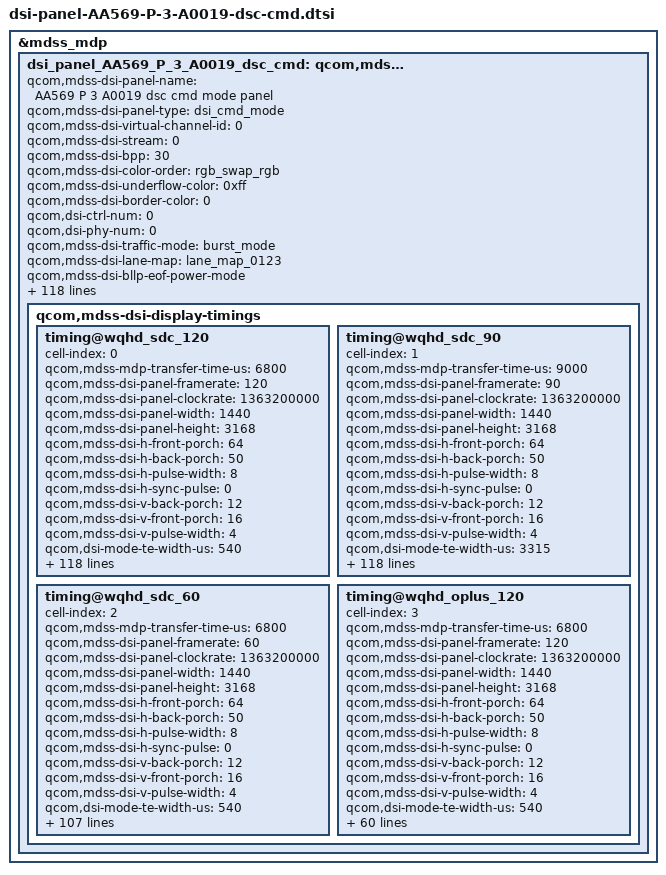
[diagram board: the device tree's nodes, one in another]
&mdss_mdp {
	dsi_panel_AA569_P_3_A0019_dsc_cmd: qcom,mdss_dsi_panel_AA569_P_3_A0019_dsc_cmd {
		qcom,mdss-dsi-panel-name = "AA569 P 3 A0019 dsc cmd mode panel";
		qcom,mdss-dsi-panel-type = "dsi_cmd_mode";
		qcom,mdss-dsi-virtual-channel-id = <0>;
		qcom,mdss-dsi-stream = <0>;
		qcom,mdss-dsi-bpp = <30>;
		qcom,mdss-dsi-color-order = "rgb_swap_rgb";
		qcom,mdss-dsi-underflow-color = <0xff>;
		qcom,mdss-dsi-border-color = <0>;
		qcom,dsi-ctrl-num = <0>;
		qcom,dsi-phy-num = <0>;
		qcom,mdss-dsi-traffic-mode = "burst_mode";
		qcom,mdss-dsi-lane-map = "lane_map_0123";
		qcom,mdss-dsi-bllp-eof-power-mode;
		qcom,mdss-dsi-bllp-power-mode;
		qcom,mdss-dsi-lane-0-state;
		qcom,mdss-dsi-lane-1-state;
		qcom,mdss-dsi-lane-2-state;
		qcom,mdss-dsi-lane-3-state;
		qcom,mdss-dsi-dma-trigger = "trigger_sw";
		qcom,mdss-dsi-mdp-trigger = "none";
		qcom,mdss-dsi-reset-sequence = <1 10>, <0 5>, <1 30>;
		qcom,mdss-pan-physical-width-dimension = <71>;
		qcom,mdss-pan-physical-height-dimension = <158>;
		qcom,mdss-dsi-te-check-enable;
		qcom,mdss-dsi-te-using-te-pin;
		qcom,mdss-dsi-te-pin-select = <1>;
		qcom,mdss-dsi-te-dcs-command = <1>;
		qcom,mdss-dsi-wr-mem-start = <0x2C>;
		qcom,mdss-dsi-wr-mem-continue = <0x3C>;
		//qcom,mdss-dsi-lp11-init;
		qcom,mdss-dsi-init-delay-us = <1000>;
		qcom,mdss-dsi-panel-jitter = <0x4 0x1>;
		/* HDR Setting */
		qcom,mdss-dsi-panel-hdr-enabled;
		qcom,mdss-dsi-panel-hdr-color-primaries = <15635 16450 34000 16000 13250 34500 7500 3000>;
		//update for [MPC15]android.mediapc.cts.PerformanceClassTest#testDisplayHdr pass
		//qcom,mdss-dsi-panel-peak-brightness = <14000000>;
		qcom,mdss-dsi-panel-peak-brightness = <20000000>;
		qcom,mdss-dsi-panel-average-brightness = <2000000>;
		qcom,mdss-dsi-panel-blackness-level = <2000>;

		qcom,mdss-dsi-display-timings {
			timing@wqhd_sdc_120 {
				#include "dsi-panel-AA569-P-3-A0019-common.dtsi"
				#include "dsi-panel-AA569-P-3-A0019-loading-effect.dtsi"
				cell-index = <0>;
				qcom,mdss-mdp-transfer-time-us = <6800>;
				qcom,mdss-dsi-panel-framerate = <120>;
				qcom,mdss-dsi-panel-clockrate = <1363200000>;
				qcom,mdss-dsi-panel-width = <1440>;
				qcom,mdss-dsi-panel-height = <3168>;
				qcom,mdss-dsi-h-front-porch = <64>;
				qcom,mdss-dsi-h-back-porch = <50>;
				qcom,mdss-dsi-h-pulse-width = <8>;
				qcom,mdss-dsi-h-sync-pulse = <0>;
				qcom,mdss-dsi-v-back-porch = <12>;
				qcom,mdss-dsi-v-front-porch = <16>;
				qcom,mdss-dsi-v-pulse-width = <4>;
				qcom,dsi-mode-te-width-us = <540>;

				qcom,mdss-dsi-timing-switch-command = [
					//120Hz
					39 00 00 40 00 00 04 FF 5A A5 00
					15 00 00 40 00 00 02 60 00
					39 00 00 40 00 00 04 FF 5A A5 2D
					39 00 00 40 00 00 03 83 00 00
					15 00 00 40 00 00 02 F2 00
					39 00 00 40 00 00 04 FF 5A A5 02
					39 00 00 40 00 00 04 B0 01 80 00
					39 00 00 00 00 00 04 FF 5A A5 00
				];
				qcom,mdss-dsi-on-command = [
					/* common setting */
					39 00 00 40 00 00 04 FF 5A A5 07
					15 00 00 40 00 00 02 8A 01
					39 00 00 40 00 00 04 FF 5A A5 31
					15 00 00 40 00 00 02 D0 80
					39 00 00 40 00 00 04 FF 5A A5 08
					15 00 00 40 00 00 02 BE 01
					39 00 00 40 00 00 04 FF 5A A5 08
					15 00 00 40 00 00 02 D2 05
					15 00 00 40 00 00 02 D3 0F
					15 00 00 40 00 00 02 D4 40
					15 00 00 40 00 00 02 F5 55
					15 00 00 40 00 00 02 F6 18
					39 00 00 40 00 00 04 FF 5A A5 21
					15 00 00 40 00 00 02 A4 18
					39 00 00 40 00 00 04 FF 5A A5 1F
					39 00 00 40 00 00 19 8F 03 08 50 0E 01 00 00 00 00 00 00 00 00 00 00 00 02 0E 00 00 08 02 00 00
					39 00 00 40 00 00 04 FF 5A A5 05
					15 00 00 40 00 00 02 9E 77
					39 00 00 40 00 00 04 FF 5A A5 14
					15 00 00 40 00 00 02 80 00
					39 00 00 40 00 00 04 FF 5A A5 17
					15 00 00 40 00 00 02 A0 00
					39 00 00 40 00 00 04 FF 5A A5 13
					15 00 00 40 00 00 02 F9 5C
					39 00 00 40 00 00 04 FF 5A A5 05
					15 00 00 40 00 00 02 85 00
					39 00 00 40 00 00 04 FF 5A A5 1C
					39 00 00 40 00 00 13 E2 0A 0A 0A 1A 1A 1A 1A 1A 0A 0A 0A 04 27 12 23 09 46 45
					39 00 00 40 00 00 04 FF 5A A5 01
					15 00 00 40 00 00 02 FB 08
					39 00 00 40 00 00 04 FF 5A A5 09
					39 00 00 40 00 00 07 8E 10 82 00 00 00 00
					39 00 00 40 00 00 04 FF 5A A5 02
					39 00 00 00 00 00 03 88 C0 00
					/* spr in ap */
					39 00 00 40 00 00 04 FF 5A A5 14
					15 00 00 40 00 00 02 82 01		//SPR IN AP MODE
					39 00 00 40 00 00 04 FF 5A A5 07
					15 00 00 40 00 00 02 91 03		//CR CB SETTING
					15 00 00 40 00 00 02 8A 01         //DSC ON
					39 00 00 40 00 00 03 8B A0 21
					39 00 00 00 00 00 64 81 00 00 00 00 00 12 00 00 AB
					                     21 00 0C 60 05 A0 00 16 02 D0
					                     02 D0 01 55 01 E2 00 0A 01 4D
					                     00 3C 00 0D 04 F4 13 A3 08 00
					                     0C 00 07 10 20 00 06 0F 0F 33
					                     0E 1C 2A 38 46 54 62 69 70 77
					                     79 7B 7D 7E 00 82 11 40 19 C0
					                     22 3E 32 7C 3A BA 3A F8 3B 38
					                     3B 38 3B 76 4B 76 4B 74 4B 74
					                     5B B4 73 F4 01 00 00 00 00 00
					/* Skip frame setting */
					39 00 00 40 00 00 04 FF 5A A5 00
					15 00 00 40 00 00 02 5E 01
					15 00 00 40 00 00 02 60 00
					15 00 00 40 00 00 02 61 0D
					39 00 00 40 00 00 04 FF 5A A5 00
					15 00 00 40 00 00 02 6D 01
					39 00 00 40 00 00 04 FF 5A A5 00
					15 00 00 40 00 00 02 35 00
					15 00 00 00 00 00 02 53 20
					//120Hz
					39 00 00 40 00 00 04 FF 5A A5 00
					15 00 00 40 00 00 02 60 00
					39 00 00 40 00 00 04 FF 5A A5 2D
					39 00 00 40 00 00 03 83 00 00
					15 00 00 40 00 00 02 F2 00
					39 00 00 40 00 00 04 FF 5A A5 02
					39 00 00 40 00 00 04 B0 01 80 00
					39 00 00 00 00 00 04 FF 5A A5 00
					// AP SPR
					39 00 00 40 00 00 04 FF 5A A5 02
					39 00 00 40 00 00 03 84 01 05
					// OPR mode
					39 00 00 40 00 00 04 FF 5A A5 1E
					39 00 00 40 00 00 04 98 99 AA 99
					39 00 00 40 00 00 0C 99 88 00 00 88 00 00 88 00 00 08 00
					15 00 00 40 00 00 02 A3 00
					// PeakLumin Dimming Off
					39 00 00 40 00 00 04 FF 5A A5 1E
					15 00 00 40 00 00 02 81 00
					39 00 00 00 00 00 04 FF 5A A5 00
					/* OSC Tracking */
					39 00 00 40 00 00 04 FF 5A A5 22
					39 00 00 40 00 00 08 D8 01 0C 11 10 32 19 19
					39 00 00 40 00 00 0A DC 84 94 BB 00 20 C4 A1 CC 10
					15 00 00 40 00 00 02 DD 01
					15 00 00 40 00 00 02 DE F1
					15 00 00 40 00 00 02 DF 80
					39 00 00 40 00 00 07 E0 02 00 5F 21 00 28
					39 00 00 00 00 00 04 FF 5A A5 00
					/* decreasing step setting */
					39 00 00 40 00 00 04 FF 5A A5 2D
					39 00 00 40 00 00 03 ED 05 00
					15 00 00 40 00 00 02 97 02
					15 00 00 40 00 00 02 98 03
					15 00 00 40 00 00 02 99 0B
					15 00 00 40 00 00 02 9A 17
					39 00 00 40 00 00 03 A0 00 02
					39 00 00 40 00 00 03 A1 02 00
					15 00 00 40 00 00 02 A4 02
					15 00 00 40 00 00 02 A5 02
					15 00 00 40 00 00 02 A6 08
					15 00 00 40 00 00 02 A7 11
					39 00 00 40 00 00 03 AD 00 02
					39 00 00 40 00 00 03 AE 02 00
					39 00 00 00 00 00 04 FF 5A A5 00
					/* partial update esd */
					39 00 00 40 00 00 04 FF 5A A5 08
					15 00 00 00 00 00 02 98 66

					05 00 00 00 78 00 01 11

					39 00 00 40 00 00 04 FF 5A A5 4F
					15 00 00 40 00 00 02 80 01
					39 00 00 40 00 00 04 FF 5A A5 53
					15 00 00 40 00 00 02 F0 01
					39 00 00 40 00 00 04 FF 5A A5 63
					39 00 00 40 00 00 11 F8 00 00 00 00 00 00 00 00 00 00 00 00 00 00 00 00
					39 00 00 40 00 00 11 F9 00 00 00 00 00 00 00 00 00 00 00 00 00 00 00 00
					39 00 00 40 00 00 11 FA 00 00 00 00 00 00 00 00 00 00 00 00 00 00 00 00
					39 00 00 40 00 00 04 FF 5A A5 53
					15 00 00 40 00 00 02 F0 00
					39 00 00 00 00 00 04 FF 5A A5 00
					/* ODC optimize drag shadow */
					39 00 00 40 00 00 04 FF 5A A5 49
					15 00 00 40 00 00 02 D9 03
					15 00 00 40 00 00 02 DA 1E
					15 00 00 40 00 00 02 DB FC
					15 00 00 40 00 00 02 DF 06
					39 00 00 00 00 00 04 FF 5A A5 00
					/* optimize crosstalk */
					39 00 00 40 00 00 04 FF 5A A5 5A
					39 00 00 40 00 00 04 81 07 1A 04
					39 00 00 40 00 00 04 8A F6 17 12
					39 00 00 40 00 00 04 8F 12 3A 33
					39 00 00 40 00 00 04 A5 09 1A 08
					39 00 00 40 00 00 04 B3 30 38 31
					39 00 00 40 00 00 04 C9 08 0D 06
					39 00 00 40 00 00 04 CA 03 06 03
					39 00 00 40 00 00 04 D7 2F 34 2D
					39 00 00 40 00 00 04 FF 5A A5 5B
					39 00 00 40 00 00 04 81 05 09 03
					39 00 00 40 00 00 04 83 02 0C 05
					39 00 00 40 00 00 04 93 00 01 07
					39 00 00 40 00 00 04 94 05 06 05
					39 00 00 40 00 00 04 A5 09 0C 04
					39 00 00 40 00 00 04 A7 FD 0F 04
					39 00 00 40 00 00 04 B7 02 07 07
					39 00 00 40 00 00 04 B8 05 07 06
					39 00 00 40 00 00 04 C9 05 07 02
					39 00 00 40 00 00 04 CA 00 00 00
					39 00 00 40 00 00 04 CB 02 09 FF
					39 00 00 40 00 00 04 DB 00 04 06
					39 00 00 40 00 00 04 DC 00 06 04
					39 00 00 40 00 00 04 FF 5A A5 5C
					39 00 00 40 00 00 04 81 00 03 02
					39 00 00 40 00 00 04 83 01 08 05
					39 00 00 40 00 00 04 93 FF 01 02
					39 00 00 40 00 00 04 94 FF 06 04
					39 00 00 40 00 00 04 A5 01 03 02
					39 00 00 40 00 00 04 B7 FF 01 06
					39 00 00 40 00 00 04 B8 FF 06 03
					39 00 00 00 00 00 04 FF 5A A5 00

					05 00 00 00 00 00 01 29
				];
				/* pwm */
				qcom,mdss-dsi-timming-pwm-switch-onepulse-command = [
					//1pulse code 120hz
					39 00 00 40 00 00 04 FF 5A A5 00
					15 00 00 40 00 00 02 60 0B
					39 00 00 40 00 00 04 FF 5A A5 2D
					39 00 00 40 00 00 03 8E 00 00
					15 00 00 40 00 00 02 F2 00
					39 00 00 40 00 00 04 FF 5A A5 02
					39 00 00 40 00 00 04 B0 01 80 00
					39 00 00 00 00 00 04 FF 5A A5 00
				];
				qcom,mdss-dsi-pwm-switch-mode0-command= [
					39 00 00 40 00 00 04 FF 5A A5 4F
					15 00 00 40 00 00 02 88 78
					39 00 00 40 00 00 04 FF 5A A5 01
					39 00 00 40 00 00 07 80 0C 00 00 00 10 19
					39 00 00 40 00 00 04 FF 5A A5 0B
					39 00 00 40 00 00 04 89 00 2F 17
					39 00 00 40 00 00 04 8A 00 00 05
					39 00 00 40 00 00 04 A8 00 0F 37
					39 00 00 40 00 00 04 A9 00 00 1F
					39 00 00 40 00 00 04 FF 5A A5 23
					15 00 00 40 00 00 02 AC 5A
					39 00 00 40 00 00 04 FF 5A A5 51
					39 00 00 40 00 00 07 C0 D6 D6 54 BE 11 01
					39 00 00 40 00 00 07 C1 78 64 64 5A 00 00
					39 00 00 40 00 00 07 C2 50 50 50 04 00 10
					39 00 00 40 00 00 04 FF 5A A5 51
					39 00 00 40 00 00 07 A0 5F 5F 5F 55 22 22
					39 00 00 40 00 00 07 A1 5A 5A 4E 75 22 22
					39 00 00 40 00 00 07 A2 70 6C 69 48 22 22
					39 00 00 40 00 00 04 FF 5A A5 52
					39 00 00 40 00 00 07 80 DA DA 57 C4 11 01
					39 00 00 40 00 00 07 81 7E 6A 70 5F 00 00
					39 00 00 40 00 00 07 82 55 56 54 04 00 10
					39 00 00 40 00 00 04 FF 5A A5 53
					39 00 00 40 00 00 03 85 CC E1
					39 00 00 40 00 00 04 FF 5A A5 1E
					39 00 00 40 00 00 1F 8E AA 62 EA EA EA AA EA EA EA EA AA EA EA EA EA AA EA EA EA EA AA EA F2 F2 F2 AA F2 F2 F2 F2
					39 00 00 40 00 00 1F 93 AA 62 EA EA EA AA EA EA EA EA AA EA EA EA EA AA EA EA EA EA AA EA F2 F2 F2 AA F2 F2 F2 F2
					39 00 00 40 00 00 04 FF 5A A5 24
					39 00 00 40 00 00 09 AC 10 ED 0F FE 0D BB 0A 81
					39 00 00 40 00 00 09 AD 06 E9 04 4D 04 3B 03 A2
					39 00 00 40 00 00 09 AE 02 8E 01 A0 00 01 00 00
					39 00 00 40 00 00 04 FF 5A A5 00
					15 00 00 40 00 00 02 60 00
					39 00 00 40 00 00 04 FF 5A A5 4F
					15 00 00 40 00 00 02 8A 78
					39 00 00 40 00 00 04 FF 5A A5 1E
					39 00 00 40 00 00 1F 8E AA 62 EA EA EA AA EA EA EA EA AA EA EA EA EA AA EA EA EA EA AA EA EA EA EA AA EA EA EA EA
					39 00 00 40 00 00 1F 93 AA 62 EA EA EA AA EA EA EA EA AA EA EA EA EA AA EA EA EA EA AA EA EA EA EA AA EA EA EA EA
					39 00 00 40 00 00 04 FF 5A A5 4F
					15 00 00 40 00 00 02 8A 78
					39 00 00 40 00 00 04 FF 5A A5 4F
					15 00 00 00 00 00 02 8B 78
				];
				qcom,mdss-dsi-pwm-switch-mode2-command = [
					39 00 00 40 00 00 04 FF 5A A5 4F
					15 00 00 40 00 00 02 88 78
					39 00 00 40 00 00 04 FF 5A A5 51
					39 00 00 40 00 00 07 C0 D6 D6 54 BE 11 01
					39 00 00 40 00 00 07 C1 78 64 64 5A 00 00
					39 00 00 40 00 00 07 C2 32 32 32 04 00 10
					39 00 00 40 00 00 04 FF 5A A5 51
					39 00 00 40 00 00 07 A0 44 44 45 3A 22 22
					39 00 00 40 00 00 07 A1 41 44 41 63 22 22
					39 00 00 40 00 00 07 A2 60 5D 5D 48 22 22
					39 00 00 40 00 00 04 FF 5A A5 52
					39 00 00 40 00 00 07 80 D6 D6 53 BC 11 01
					39 00 00 40 00 00 07 81 74 63 63 55 00 00
					39 00 00 40 00 00 07 82 2F 2F 2F 04 00 10
					39 00 00 40 00 00 04 FF 5A A5 53
					39 00 00 40 00 00 03 85 CC E3
					39 00 00 40 00 00 04 FF 5A A5 1E
					39 00 00 40 00 00 1F 8E AA 54 DC DC DC AA DC DC DC DC AA DC DC DC DC AA DC DC DC DC AA DC D0 D0 D0 AA D0 D0 D0 D0
					39 00 00 40 00 00 1F 93 AA 54 DC DC DC AA DC DC DC DC AA DC DC DC DC AA DC DC DC DC AA DC D0 D0 D0 AA D0 D0 D0 D0
					39 00 00 40 00 00 04 FF 5A A5 24
					39 00 00 40 00 00 09 AC 10 ED 0F FE 0D BB 0A 81
					39 00 00 40 00 00 09 AD 06 E9 04 4D 03 A2 02 8E
					39 00 00 40 00 00 09 AE 01 A0 00 01 00 00 00 00
					39 00 00 40 00 00 04 FF 5A A5 00
					15 00 00 40 00 00 02 60 0B
					39 00 00 40 00 00 04 FF 5A A5 4F
					15 00 00 40 00 00 02 8A 78
					39 00 00 40 00 00 04 FF 5A A5 01
					39 00 00 40 00 00 07 80 0C 00 00 00 10 29
					39 00 00 40 00 00 04 FF 5A A5 23
					15 00 00 40 00 00 02 AC 1A
					39 00 00 40 00 00 04 FF 5A A5 0B
					39 00 00 40 00 00 04 89 00 3F 07
					39 00 00 40 00 00 04 8A 00 05 05
					39 00 00 40 00 00 04 A8 00 0F 37
					39 00 00 40 00 00 04 A9 00 0B 1F
					39 00 00 40 00 00 04 FF 5A A5 1E
					39 00 00 40 00 00 1F 8E AA 62 EA EA EA AA EA EA EA EA AA EA EA EA EA AA EA EA EA EA AA EA EA EA EA AA EA EA EA EA
					39 00 00 40 00 00 1F 93 AA 62 EA EA EA AA EA EA EA EA AA EA EA EA EA AA EA EA EA EA AA EA EA EA EA AA EA EA EA EA
					39 00 00 40 00 00 04 FF 5A A5 4F
					15 00 00 40 00 00 02 8A 78
					39 00 00 40 00 00 04 FF 5A A5 4F
					15 00 00 00 00 00 02 8B 78
				];
				qcom,mdss-dsi-pwm-switch-mode2-panel-on-command = [
					39 00 00 40 00 00 04 FF 5A A5 4F
					15 00 00 40 00 00 02 88 78
					39 00 00 40 00 00 04 FF 5A A5 51
					39 00 00 40 00 00 07 C0 D6 D6 54 BE 11 01
					39 00 00 40 00 00 07 C1 78 64 64 5A 00 00
					39 00 00 40 00 00 07 C2 32 32 32 04 00 10
					39 00 00 40 00 00 04 FF 5A A5 51
					39 00 00 40 00 00 07 A0 44 44 45 3A 22 22
					39 00 00 40 00 00 07 A1 41 44 41 63 22 22
					39 00 00 40 00 00 07 A2 60 5D 5D 48 22 22
					39 00 00 40 00 00 04 FF 5A A5 52
					39 00 00 40 00 00 07 80 D6 D6 53 BC 11 01
					39 00 00 40 00 00 07 81 74 63 63 55 00 00
					39 00 00 40 00 00 07 82 2F 2F 2F 04 00 10
					39 00 00 40 00 00 04 FF 5A A5 53
					39 00 00 40 00 00 03 85 CC E3
					39 00 00 40 00 00 04 FF 5A A5 1E
					39 00 00 40 00 00 1F 8E AA 54 DC DC DC AA DC DC DC DC AA DC DC DC DC AA DC DC DC DC AA DC D0 D0 D0 AA D0 D0 D0 D0
					39 00 00 40 00 00 1F 93 AA 54 DC DC DC AA DC DC DC DC AA DC DC DC DC AA DC DC DC DC AA DC D0 D0 D0 AA D0 D0 D0 D0
					39 00 00 40 00 00 04 FF 5A A5 24
					39 00 00 40 00 00 09 AC 10 ED 0F FE 0D BB 0A 81
					39 00 00 40 00 00 09 AD 06 E9 04 4D 03 A2 02 8E
					39 00 00 40 00 00 09 AE 01 A0 00 01 00 00 00 00
					39 00 00 40 00 00 04 FF 5A A5 00
					15 00 00 40 00 00 02 60 0B
					39 00 00 40 00 00 04 FF 5A A5 4F
					15 00 00 40 00 00 02 8A 78
					39 00 00 40 00 00 04 FF 5A A5 01
					39 00 00 40 00 00 07 80 0C 00 00 00 10 29
					39 00 00 40 00 00 04 FF 5A A5 23
					15 00 00 40 00 00 02 AC 1A
					39 00 00 40 00 00 04 FF 5A A5 0B
					39 00 00 40 00 00 04 89 00 3F 07
					39 00 00 40 00 00 04 8A 00 05 05
					39 00 00 40 00 00 04 A8 00 0F 37
					39 00 00 40 00 00 04 A9 00 0B 1F
					39 00 00 40 00 00 04 FF 5A A5 1E
					39 00 00 40 00 00 1F 8E AA 62 EA EA EA AA EA EA EA EA AA EA EA EA EA AA EA EA EA EA AA EA EA EA EA AA EA EA EA EA
					39 00 00 40 00 00 1F 93 AA 62 EA EA EA AA EA EA EA EA AA EA EA EA EA AA EA EA EA EA AA EA EA EA EA AA EA EA EA EA
					39 00 00 40 00 00 04 FF 5A A5 4F
					15 00 00 40 00 00 02 8A 78
					39 00 00 40 00 00 04 FF 5A A5 4F
					15 00 00 00 09 00 02 8B 78
				];
				qcom,mdss-dsi-pwm-switch-low-bl-command = [
					39 00 00 40 00 00 04 FF 5A A5 4F
					15 00 00 40 00 00 02 88 78
					39 00 00 40 00 00 04 FF 5A A5 01
					39 00 00 40 00 00 07 80 0C 00 00 00 10 19
					39 00 00 40 00 00 04 FF 5A A5 0B
					39 00 00 40 00 00 04 89 00 2F 17
					39 00 00 40 00 00 04 8A 00 00 05
					39 00 00 40 00 00 04 A8 00 0F 37
					39 00 00 40 00 00 04 A9 00 00 1F
					39 00 00 40 00 00 04 FF 5A A5 23
					15 00 00 40 00 00 02 AC 5A
					39 00 00 40 00 00 04 FF 5A A5 51
					39 00 00 40 00 00 07 C0 D6 D6 54 BE 11 01
					39 00 00 40 00 00 07 C1 78 64 64 5A 00 00
					39 00 00 40 00 00 07 C2 50 50 50 04 00 10
					39 00 00 40 00 00 04 FF 5A A5 51
					39 00 00 40 00 00 07 A0 5F 5F 5F 55 22 22
					39 00 00 40 00 00 07 A1 5A 5A 4E 75 22 22
					39 00 00 40 00 00 07 A2 70 6C 69 48 22 22
					39 00 00 40 00 00 04 FF 5A A5 52
					39 00 00 40 00 00 07 80 DA DA 57 C4 11 01
					39 00 00 40 00 00 07 81 7E 6A 70 5F 00 00
					39 00 00 40 00 00 07 82 55 56 54 04 00 10
					39 00 00 40 00 00 04 FF 5A A5 53
					39 00 00 40 00 00 03 85 CC E1
					39 00 00 40 00 00 04 FF 5A A5 1E
					39 00 00 40 00 00 1F 8E AA 62 EA EA EA AA EA EA EA EA AA EA EA EA EA AA EA EA EA EA AA EA F2 F2 F2 AA F2 F2 F2 F2
					39 00 00 40 00 00 1F 93 AA 62 EA EA EA AA EA EA EA EA AA EA EA EA EA AA EA EA EA EA AA EA F2 F2 F2 AA F2 F2 F2 F2
					39 00 00 40 00 00 04 FF 5A A5 00
					39 00 00 40 00 00 03 51 04 4D
					15 00 00 40 00 00 02 60 00
					39 00 00 40 00 00 04 FF 5A A5 24
					39 00 00 40 00 00 09 AC 10 ED 0F FE 0D BB 0A 81
					39 00 00 40 00 00 09 AD 06 E9 04 4D 04 3B 03 A2
					39 00 00 40 00 00 09 AE 02 8E 01 A0 00 01 00 00
					39 00 00 40 00 00 04 FF 5A A5 4F
					15 00 00 40 00 00 02 8A 78
					39 00 00 40 00 00 04 FF 5A A5 1E
					39 00 00 40 00 00 1F 8E AA 62 EA EA EA AA EA EA EA EA AA EA EA EA EA AA EA EA EA EA AA EA EA EA EA AA EA EA EA EA
					39 00 00 40 00 00 1F 93 AA 62 EA EA EA AA EA EA EA EA AA EA EA EA EA AA EA EA EA EA AA EA EA EA EA AA EA EA EA EA
					39 00 00 40 00 00 04 FF 5A A5 4F
					15 00 00 00 00 00 02 8B 78
				];
				qcom,mdss-dsi-pwm-switch-high-bl-command = [
					39 00 00 40 00 00 04 FF 5A A5 4F
					15 00 00 40 00 00 02 88 78
					39 00 00 40 00 00 04 FF 5A A5 51
					39 00 00 40 00 00 07 C0 D6 D6 54 BE 11 01
					39 00 00 40 00 00 07 C1 78 64 64 5A 00 00
					39 00 00 40 00 00 07 C2 32 32 32 04 00 10
					39 00 00 40 00 00 04 FF 5A A5 51
					39 00 00 40 00 00 07 A0 44 44 45 3A 22 22
					39 00 00 40 00 00 07 A1 41 44 41 63 22 22
					39 00 00 40 00 00 07 A2 60 5D 5D 48 22 22
					39 00 00 40 00 00 04 FF 5A A5 52
					39 00 00 40 00 00 07 80 D6 D6 53 BC 11 01
					39 00 00 40 00 00 07 81 74 63 63 55 00 00
					39 00 00 40 00 00 07 82 2F 2F 2F 04 00 10
					39 00 00 40 00 00 04 FF 5A A5 53
					39 00 00 40 00 00 03 85 CC E3
					39 00 00 40 00 00 04 FF 5A A5 1E
					39 00 00 40 00 00 1F 8E AA 54 DC DC DC AA DC DC DC DC AA DC DC DC DC AA DC DC DC DC AA DC D0 D0 D0 AA D0 D0 D0 D0
					39 00 00 40 00 00 1F 93 AA 54 DC DC DC AA DC DC DC DC AA DC DC DC DC AA DC DC DC DC AA DC D0 D0 D0 AA D0 D0 D0 D0
					39 00 00 40 00 00 04 FF 5A A5 00
					39 00 00 40 00 00 03 51 04 4D
					15 00 00 40 00 00 02 60 0B
					39 00 00 40 00 00 04 FF 5A A5 24
					39 00 00 40 00 00 09 AC 10 ED 0F FE 0D BB 0A 81
					39 00 00 40 00 00 09 AD 06 E9 04 4D 03 A2 02 8E
					39 00 00 40 00 00 09 AE 01 A0 00 01 00 00 00 00
					39 00 00 40 00 00 04 FF 5A A5 4F
					15 00 00 40 00 00 02 8A 78
					39 00 00 40 00 00 04 FF 5A A5 01
					39 00 00 40 00 00 07 80 0C 00 00 00 10 29
					39 00 00 40 00 00 04 FF 5A A5 23
					15 00 00 40 00 00 02 AC 1A
					39 00 00 40 00 00 04 FF 5A A5 0B
					39 00 00 40 00 00 04 89 00 3F 07
					39 00 00 40 00 00 04 8A 00 05 05
					39 00 00 40 00 00 04 A8 00 0F 37
					39 00 00 40 00 00 04 A9 00 0B 1F
					39 00 00 40 00 00 04 FF 5A A5 1E
					39 00 00 40 00 00 1F 8E AA 62 EA EA EA AA EA EA EA EA AA EA EA EA EA AA EA EA EA EA AA EA EA EA EA AA EA EA EA EA
					39 00 00 40 00 00 1F 93 AA 62 EA EA EA AA EA EA EA EA AA EA EA EA EA AA EA EA EA EA AA EA EA EA EA AA EA EA EA EA
					39 00 00 40 00 00 04 FF 5A A5 4F
					15 00 00 00 00 00 02 8B 78
				];

				//qcom,panel-roi-alignment=<1080 44 1080 44 1080 44>;
				//qcom,partial-update-enabled = "single_roi";

				qcom,lm-split = <720 720>;
				qcom,mdss-dsc-slice-height = <22>;
				qcom,mdss-dsc-slice-width = <720>;
			};
			timing@wqhd_sdc_90 {
				#include "dsi-panel-AA569-P-3-A0019-common.dtsi"
				#include "dsi-panel-AA569-P-3-A0019-loading-effect.dtsi"
				cell-index = <1>;
				qcom,mdss-mdp-transfer-time-us = <9000>;
				qcom,mdss-dsi-panel-framerate = <90>;
				qcom,mdss-dsi-panel-clockrate = <1363200000>;
				qcom,mdss-dsi-panel-width = <1440>;
				qcom,mdss-dsi-panel-height = <3168>;
				qcom,mdss-dsi-h-front-porch = <64>;
				qcom,mdss-dsi-h-back-porch = <50>;
				qcom,mdss-dsi-h-pulse-width = <8>;
				qcom,mdss-dsi-h-sync-pulse = <0>;
				qcom,mdss-dsi-v-back-porch = <12>;
				qcom,mdss-dsi-v-front-porch = <16>;
				qcom,mdss-dsi-v-pulse-width = <4>;
				qcom,dsi-mode-te-width-us = <3315>;

				qcom,mdss-dsi-timing-switch-command = [
					//90Hz
					39 00 00 40 00 00 04 FF 5A A5 00
					15 00 00 40 00 00 02 60 07
					39 00 00 40 00 00 04 FF 5A A5 2D
					39 00 00 40 00 00 03 8A 00 00
					15 00 00 40 00 00 02 F2 00
					39 00 00 40 00 00 04 FF 5A A5 02
					39 00 00 40 00 00 04 B0 01 80 00
					39 00 00 00 00 00 04 FF 5A A5 00
				];
				qcom,mdss-dsi-on-command = [
					/* common setting */
					39 00 00 40 00 00 04 FF 5A A5 07
					15 00 00 40 00 00 02 8A 01
					39 00 00 40 00 00 04 FF 5A A5 31
					15 00 00 40 00 00 02 D0 80
					39 00 00 40 00 00 04 FF 5A A5 08
					15 00 00 40 00 00 02 BE 01
					39 00 00 40 00 00 04 FF 5A A5 08
					15 00 00 40 00 00 02 D2 05
					15 00 00 40 00 00 02 D3 0F
					15 00 00 40 00 00 02 D4 40
					15 00 00 40 00 00 02 F5 55
					15 00 00 40 00 00 02 F6 18
					39 00 00 40 00 00 04 FF 5A A5 21
					15 00 00 40 00 00 02 A4 18
					39 00 00 40 00 00 04 FF 5A A5 1F
					39 00 00 40 00 00 19 8F 03 08 50 0E 01 00 00 00 00 00 00 00 00 00 00 00 02 0E 00 00 08 02 00 00
					39 00 00 40 00 00 04 FF 5A A5 05
					15 00 00 40 00 00 02 9E 77
					39 00 00 40 00 00 04 FF 5A A5 14
					15 00 00 40 00 00 02 80 00
					39 00 00 40 00 00 04 FF 5A A5 17
					15 00 00 40 00 00 02 A0 00
					39 00 00 40 00 00 04 FF 5A A5 13
					15 00 00 40 00 00 02 F9 5C
					39 00 00 40 00 00 04 FF 5A A5 05
					15 00 00 40 00 00 02 85 00
					39 00 00 40 00 00 04 FF 5A A5 1C
					39 00 00 40 00 00 13 E2 0A 0A 0A 1A 1A 1A 1A 1A 0A 0A 0A 04 27 12 23 09 46 45
					39 00 00 40 00 00 04 FF 5A A5 01
					15 00 00 40 00 00 02 FB 08
					39 00 00 40 00 00 04 FF 5A A5 09
					39 00 00 40 00 00 07 8E 10 82 00 00 00 00
					39 00 00 40 00 00 04 FF 5A A5 02
					39 00 00 00 00 00 03 88 C0 00
					/* spr in ap */
					39 00 00 40 00 00 04 FF 5A A5 14
					15 00 00 40 00 00 02 82 01		//SPR IN AP MODE
					39 00 00 40 00 00 04 FF 5A A5 07
					15 00 00 40 00 00 02 91 03		//CR CB SETTING
					15 00 00 40 00 00 02 8A 01         //DSC ON
					39 00 00 40 00 00 03 8B A0 21
					39 00 00 00 00 00 64 81 00 00 00 00 00 12 00 00 AB
					                     21 00 0C 60 05 A0 00 16 02 D0
					                     02 D0 01 55 01 E2 00 0A 01 4D
					                     00 3C 00 0D 04 F4 13 A3 08 00
					                     0C 00 07 10 20 00 06 0F 0F 33
					                     0E 1C 2A 38 46 54 62 69 70 77
					                     79 7B 7D 7E 00 82 11 40 19 C0
					                     22 3E 32 7C 3A BA 3A F8 3B 38
					                     3B 38 3B 76 4B 76 4B 74 4B 74
					                     5B B4 73 F4 01 00 00 00 00 00
					/* Skip frame setting */
					39 00 00 40 00 00 04 FF 5A A5 00
					15 00 00 40 00 00 02 5E 01
					15 00 00 40 00 00 02 60 00
					15 00 00 40 00 00 02 61 0D
					39 00 00 40 00 00 04 FF 5A A5 00
					15 00 00 40 00 00 02 6D 01
					39 00 00 40 00 00 04 FF 5A A5 00
					15 00 00 40 00 00 02 35 00
					15 00 00 00 00 00 02 53 20
					//90Hz
					39 00 00 40 00 00 04 FF 5A A5 00
					15 00 00 40 00 00 02 60 07
					39 00 00 40 00 00 04 FF 5A A5 2D
					39 00 00 40 00 00 03 8A 00 00
					15 00 00 40 00 00 02 F2 00
					39 00 00 40 00 00 04 FF 5A A5 02
					39 00 00 40 00 00 04 B0 01 80 00
					39 00 00 00 00 00 04 FF 5A A5 00
					// AP SPR
					39 00 00 40 00 00 04 FF 5A A5 02
					39 00 00 40 00 00 03 84 01 05
					// OPR mode
					39 00 00 40 00 00 04 FF 5A A5 1E
					39 00 00 40 00 00 04 98 99 AA 99
					39 00 00 40 00 00 0C 99 88 00 00 88 00 00 88 00 00 08 00
					15 00 00 40 00 00 02 A3 00
					// PeakLumin Dimming Off
					39 00 00 40 00 00 04 FF 5A A5 1E
					15 00 00 40 00 00 02 81 00
					39 00 00 00 00 00 04 FF 5A A5 00
					/* OSC Tracking */
					39 00 00 40 00 00 04 FF 5A A5 22
					39 00 00 40 00 00 08 D8 01 0C 11 10 32 19 19
					39 00 00 40 00 00 0A DC 84 94 BB 00 20 C4 A1 CC 10
					15 00 00 40 00 00 02 DD 01
					15 00 00 40 00 00 02 DE F1
					15 00 00 40 00 00 02 DF 80
					39 00 00 40 00 00 07 E0 02 00 5F 21 00 28
					39 00 00 00 00 00 04 FF 5A A5 00
					/* decreasing step setting */
					39 00 00 40 00 00 04 FF 5A A5 2D
					39 00 00 40 00 00 03 ED 05 00
					15 00 00 40 00 00 02 97 02
					15 00 00 40 00 00 02 98 03
					15 00 00 40 00 00 02 99 0B
					15 00 00 40 00 00 02 9A 17
					39 00 00 40 00 00 03 A0 00 02
					39 00 00 40 00 00 03 A1 02 00
					15 00 00 40 00 00 02 A4 02
					15 00 00 40 00 00 02 A5 02
					15 00 00 40 00 00 02 A6 08
					15 00 00 40 00 00 02 A7 11
					39 00 00 40 00 00 03 AD 00 02
					39 00 00 40 00 00 03 AE 02 00
					39 00 00 00 00 00 04 FF 5A A5 00
					/* partial update esd */
					39 00 00 40 00 00 04 FF 5A A5 08
					15 00 00 00 00 00 02 98 66

					05 00 00 00 78 00 01 11

					39 00 00 40 00 00 04 FF 5A A5 4F
					15 00 00 40 00 00 02 80 01
					39 00 00 40 00 00 04 FF 5A A5 53
					15 00 00 40 00 00 02 F0 01
					39 00 00 40 00 00 04 FF 5A A5 63
					39 00 00 40 00 00 11 F8 00 00 00 00 00 00 00 00 00 00 00 00 00 00 00 00
					39 00 00 40 00 00 11 F9 00 00 00 00 00 00 00 00 00 00 00 00 00 00 00 00
					39 00 00 40 00 00 11 FA 00 00 00 00 00 00 00 00 00 00 00 00 00 00 00 00
					39 00 00 40 00 00 04 FF 5A A5 53
					15 00 00 40 00 00 02 F0 00
					39 00 00 00 00 00 04 FF 5A A5 00
					/* ODC optimize drag shadow */
					39 00 00 40 00 00 04 FF 5A A5 49
					15 00 00 40 00 00 02 D9 03
					15 00 00 40 00 00 02 DA 1E
					15 00 00 40 00 00 02 DB FC
					15 00 00 40 00 00 02 DF 06
					39 00 00 00 00 00 04 FF 5A A5 00
					/* optimize crosstalk */
					39 00 00 40 00 00 04 FF 5A A5 5A
					39 00 00 40 00 00 04 81 07 1A 04
					39 00 00 40 00 00 04 8A F6 17 12
					39 00 00 40 00 00 04 8F 12 3A 33
					39 00 00 40 00 00 04 A5 09 1A 08
					39 00 00 40 00 00 04 B3 30 38 31
					39 00 00 40 00 00 04 C9 08 0D 06
					39 00 00 40 00 00 04 CA 03 06 03
					39 00 00 40 00 00 04 D7 2F 34 2D
					39 00 00 40 00 00 04 FF 5A A5 5B
					39 00 00 40 00 00 04 81 05 09 03
					39 00 00 40 00 00 04 83 02 0C 05
					39 00 00 40 00 00 04 93 00 01 07
					39 00 00 40 00 00 04 94 05 06 05
					39 00 00 40 00 00 04 A5 09 0C 04
					39 00 00 40 00 00 04 A7 FD 0F 04
					39 00 00 40 00 00 04 B7 02 07 07
					39 00 00 40 00 00 04 B8 05 07 06
					39 00 00 40 00 00 04 C9 05 07 02
					39 00 00 40 00 00 04 CA 00 00 00
					39 00 00 40 00 00 04 CB 02 09 FF
					39 00 00 40 00 00 04 DB 00 04 06
					39 00 00 40 00 00 04 DC 00 06 04
					39 00 00 40 00 00 04 FF 5A A5 5C
					39 00 00 40 00 00 04 81 00 03 02
					39 00 00 40 00 00 04 83 01 08 05
					39 00 00 40 00 00 04 93 FF 01 02
					39 00 00 40 00 00 04 94 FF 06 04
					39 00 00 40 00 00 04 A5 01 03 02
					39 00 00 40 00 00 04 B7 FF 01 06
					39 00 00 40 00 00 04 B8 FF 06 03
					39 00 00 00 00 00 04 FF 5A A5 00

					05 00 00 00 00 00 01 29
				];
				/* pwm */
				qcom,mdss-dsi-timming-pwm-switch-onepulse-command = [
					//1pulse code 90hz
					39 00 00 40 00 00 04 FF 5A A5 00
					15 00 00 40 00 00 02 60 0C
					39 00 00 40 00 00 04 FF 5A A5 2D
					39 00 00 40 00 00 03 8F 00 00
					15 00 00 40 00 00 02 F2 00
					39 00 00 40 00 00 04 FF 5A A5 02
					39 00 00 40 00 00 04 B0 01 80 00
					39 00 00 00 00 00 04 FF 5A A5 00
				];
				qcom,mdss-dsi-pwm-switch-mode0-command= [
					39 00 00 40 00 00 04 FF 5A A5 4F
					15 00 00 40 00 00 02 88 78
					39 00 00 40 00 00 04 FF 5A A5 01
					39 00 00 40 00 00 07 80 0C 00 00 00 10 19
					39 00 00 40 00 00 04 FF 5A A5 0B
					39 00 00 40 00 00 04 89 00 2F 17
					39 00 00 40 00 00 04 8A 00 00 05
					39 00 00 40 00 00 04 A8 00 0F 37
					39 00 00 40 00 00 04 A9 00 00 1F
					39 00 00 40 00 00 04 FF 5A A5 23
					15 00 00 40 00 00 02 AC 5A
					39 00 00 40 00 00 04 FF 5A A5 51
					39 00 00 40 00 00 07 C0 D6 D6 54 BE 11 01
					39 00 00 40 00 00 07 C1 78 64 64 5A 00 00
					39 00 00 40 00 00 07 C2 50 50 50 04 00 10
					39 00 00 40 00 00 04 FF 5A A5 51
					39 00 00 40 00 00 07 A0 5F 5F 5F 55 22 22
					39 00 00 40 00 00 07 A1 5A 5A 4E 75 22 22
					39 00 00 40 00 00 07 A2 70 6C 69 48 22 22
					39 00 00 40 00 00 04 FF 5A A5 52
					39 00 00 40 00 00 07 80 DA DA 57 C4 11 01
					39 00 00 40 00 00 07 81 7E 6A 70 5F 00 00
					39 00 00 40 00 00 07 82 55 56 54 04 00 10
					39 00 00 40 00 00 04 FF 5A A5 53
					39 00 00 40 00 00 03 85 CC E1
					39 00 00 40 00 00 04 FF 5A A5 1E
					39 00 00 40 00 00 1F 8E AA 62 EA EA EA AA EA EA EA EA AA EA EA EA EA AA EA EA EA EA AA EA F2 F2 F2 AA F2 F2 F2 F2
					39 00 00 40 00 00 1F 93 AA 62 EA EA EA AA EA EA EA EA AA EA EA EA EA AA EA EA EA EA AA EA F2 F2 F2 AA F2 F2 F2 F2
					39 00 00 40 00 00 04 FF 5A A5 24
					39 00 00 40 00 00 09 AC 10 ED 0F FE 0D BB 0A 81
					39 00 00 40 00 00 09 AD 06 E9 04 4D 04 3B 03 A2
					39 00 00 40 00 00 09 AE 02 8E 01 A0 00 01 00 00
					39 00 00 40 00 00 04 FF 5A A5 00
					15 00 00 40 00 00 02 60 07
					39 00 00 40 00 00 04 FF 5A A5 4F
					15 00 00 40 00 00 02 8A 78
					39 00 00 40 00 00 04 FF 5A A5 1E
					39 00 00 40 00 00 1F 8E AA 62 EA EA EA AA EA EA EA EA AA EA EA EA EA AA EA EA EA EA AA EA EA EA EA AA EA EA EA EA
					39 00 00 40 00 00 1F 93 AA 62 EA EA EA AA EA EA EA EA AA EA EA EA EA AA EA EA EA EA AA EA EA EA EA AA EA EA EA EA
					39 00 00 40 00 00 04 FF 5A A5 4F
					15 00 00 40 00 00 02 8A 78
					39 00 00 40 00 00 04 FF 5A A5 4F
					15 00 00 00 00 00 02 8B 78
				];
				qcom,mdss-dsi-pwm-switch-mode2-command = [
					39 00 00 40 00 00 04 FF 5A A5 4F
					15 00 00 40 00 00 02 88 78
					39 00 00 40 00 00 04 FF 5A A5 51
					39 00 00 40 00 00 07 C0 D6 D6 54 BE 11 01
					39 00 00 40 00 00 07 C1 78 64 64 5A 00 00
					39 00 00 40 00 00 07 C2 32 32 32 04 00 10
					39 00 00 40 00 00 04 FF 5A A5 51
					39 00 00 40 00 00 07 A0 44 44 45 3A 22 22
					39 00 00 40 00 00 07 A1 41 44 41 63 22 22
					39 00 00 40 00 00 07 A2 60 5D 5D 48 22 22
					39 00 00 40 00 00 04 FF 5A A5 52
					39 00 00 40 00 00 07 80 D6 D6 53 BC 11 01
					39 00 00 40 00 00 07 81 74 63 63 55 00 00
					39 00 00 40 00 00 07 82 2F 2F 2F 04 00 10
					39 00 00 40 00 00 04 FF 5A A5 53
					39 00 00 40 00 00 03 85 CC E3
					39 00 00 40 00 00 04 FF 5A A5 1E
					39 00 00 40 00 00 1F 8E AA 54 DC DC DC AA DC DC DC DC AA DC DC DC DC AA DC DC DC DC AA DC D0 D0 D0 AA D0 D0 D0 D0
					39 00 00 40 00 00 1F 93 AA 54 DC DC DC AA DC DC DC DC AA DC DC DC DC AA DC DC DC DC AA DC D0 D0 D0 AA D0 D0 D0 D0
					39 00 00 40 00 00 04 FF 5A A5 24
					39 00 00 40 00 00 09 AC 10 ED 0F FE 0D BB 0A 81
					39 00 00 40 00 00 09 AD 06 E9 04 4D 03 A2 02 8E
					39 00 00 40 00 00 09 AE 01 A0 00 01 00 00 00 00
					39 00 00 40 00 00 04 FF 5A A5 00
					15 00 00 40 00 00 02 60 0C
					39 00 00 40 00 00 04 FF 5A A5 4F
					15 00 00 40 00 00 02 8A 78
					39 00 00 40 00 00 04 FF 5A A5 01
					39 00 00 40 00 00 07 80 0C 00 00 00 10 29
					39 00 00 40 00 00 04 FF 5A A5 23
					15 00 00 40 00 00 02 AC 1A
					39 00 00 40 00 00 04 FF 5A A5 0B
					39 00 00 40 00 00 04 89 00 3F 07
					39 00 00 40 00 00 04 8A 00 05 05
					39 00 00 40 00 00 04 A8 00 0F 37
					39 00 00 40 00 00 04 A9 00 0B 1F
					39 00 00 40 00 00 04 FF 5A A5 1E
					39 00 00 40 00 00 1F 8E AA 62 EA EA EA AA EA EA EA EA AA EA EA EA EA AA EA EA EA EA AA EA EA EA EA AA EA EA EA EA
					39 00 00 40 00 00 1F 93 AA 62 EA EA EA AA EA EA EA EA AA EA EA EA EA AA EA EA EA EA AA EA EA EA EA AA EA EA EA EA
					39 00 00 40 00 00 04 FF 5A A5 4F
					15 00 00 40 00 00 02 8A 78
					39 00 00 40 00 00 04 FF 5A A5 4F
					15 00 00 00 00 00 02 8B 78
				];
				qcom,mdss-dsi-pwm-switch-mode2-panel-on-command = [
					39 00 00 40 00 00 04 FF 5A A5 4F
					15 00 00 40 00 00 02 88 78
					39 00 00 40 00 00 04 FF 5A A5 51
					39 00 00 40 00 00 07 C0 D6 D6 54 BE 11 01
					39 00 00 40 00 00 07 C1 78 64 64 5A 00 00
					39 00 00 40 00 00 07 C2 32 32 32 04 00 10
					39 00 00 40 00 00 04 FF 5A A5 51
					39 00 00 40 00 00 07 A0 44 44 45 3A 22 22
					39 00 00 40 00 00 07 A1 41 44 41 63 22 22
					39 00 00 40 00 00 07 A2 60 5D 5D 48 22 22
					39 00 00 40 00 00 04 FF 5A A5 52
					39 00 00 40 00 00 07 80 D6 D6 53 BC 11 01
					39 00 00 40 00 00 07 81 74 63 63 55 00 00
					39 00 00 40 00 00 07 82 2F 2F 2F 04 00 10
					39 00 00 40 00 00 04 FF 5A A5 53
					39 00 00 40 00 00 03 85 CC E3
					39 00 00 40 00 00 04 FF 5A A5 1E
					39 00 00 40 00 00 1F 8E AA 54 DC DC DC AA DC DC DC DC AA DC DC DC DC AA DC DC DC DC AA DC D0 D0 D0 AA D0 D0 D0 D0
					39 00 00 40 00 00 1F 93 AA 54 DC DC DC AA DC DC DC DC AA DC DC DC DC AA DC DC DC DC AA DC D0 D0 D0 AA D0 D0 D0 D0
					39 00 00 40 00 00 04 FF 5A A5 24
					39 00 00 40 00 00 09 AC 10 ED 0F FE 0D BB 0A 81
					39 00 00 40 00 00 09 AD 06 E9 04 4D 03 A2 02 8E
					39 00 00 40 00 00 09 AE 01 A0 00 01 00 00 00 00
					39 00 00 40 00 00 04 FF 5A A5 00
					15 00 00 40 00 00 02 60 0C
					39 00 00 40 00 00 04 FF 5A A5 4F
					15 00 00 40 00 00 02 8A 78
					39 00 00 40 00 00 04 FF 5A A5 01
					39 00 00 40 00 00 07 80 0C 00 00 00 10 29
					39 00 00 40 00 00 04 FF 5A A5 23
					15 00 00 40 00 00 02 AC 1A
					39 00 00 40 00 00 04 FF 5A A5 0B
					39 00 00 40 00 00 04 89 00 3F 07
					39 00 00 40 00 00 04 8A 00 05 05
					39 00 00 40 00 00 04 A8 00 0F 37
					39 00 00 40 00 00 04 A9 00 0B 1F
					39 00 00 40 00 00 04 FF 5A A5 1E
					39 00 00 40 00 00 1F 8E AA 62 EA EA EA AA EA EA EA EA AA EA EA EA EA AA EA EA EA EA AA EA EA EA EA AA EA EA EA EA
					39 00 00 40 00 00 1F 93 AA 62 EA EA EA AA EA EA EA EA AA EA EA EA EA AA EA EA EA EA AA EA EA EA EA AA EA EA EA EA
					39 00 00 40 00 00 04 FF 5A A5 4F
					15 00 00 40 00 00 02 8A 78
					39 00 00 40 00 00 04 FF 5A A5 4F
					15 00 00 00 0C 00 02 8B 78
				];
				qcom,mdss-dsi-pwm-switch-low-bl-command = [
					39 00 00 40 00 00 04 FF 5A A5 4F
					15 00 00 40 00 00 02 88 78
					39 00 00 40 00 00 04 FF 5A A5 01
					39 00 00 40 00 00 07 80 0C 00 00 00 10 19
					39 00 00 40 00 00 04 FF 5A A5 0B
					39 00 00 40 00 00 04 89 00 2F 17
					39 00 00 40 00 00 04 8A 00 00 05
					39 00 00 40 00 00 04 A8 00 0F 37
					39 00 00 40 00 00 04 A9 00 00 1F
					39 00 00 40 00 00 04 FF 5A A5 23
					15 00 00 40 00 00 02 AC 5A
					39 00 00 40 00 00 04 FF 5A A5 51
					39 00 00 40 00 00 07 C0 D6 D6 54 BE 11 01
					39 00 00 40 00 00 07 C1 78 64 64 5A 00 00
					39 00 00 40 00 00 07 C2 50 50 50 04 00 10
					39 00 00 40 00 00 04 FF 5A A5 51
					39 00 00 40 00 00 07 A0 5F 5F 5F 55 22 22
					39 00 00 40 00 00 07 A1 5A 5A 4E 75 22 22
					39 00 00 40 00 00 07 A2 70 6C 69 48 22 22
					39 00 00 40 00 00 04 FF 5A A5 52
					39 00 00 40 00 00 07 80 DA DA 57 C4 11 01
					39 00 00 40 00 00 07 81 7E 6A 70 5F 00 00
					39 00 00 40 00 00 07 82 55 56 54 04 00 10
					39 00 00 40 00 00 04 FF 5A A5 53
					39 00 00 40 00 00 03 85 CC E1
					39 00 00 40 00 00 04 FF 5A A5 1E
					39 00 00 40 00 00 1F 8E AA 62 EA EA EA AA EA EA EA EA AA EA EA EA EA AA EA EA EA EA AA EA F2 F2 F2 AA F2 F2 F2 F2
					39 00 00 40 00 00 1F 93 AA 62 EA EA EA AA EA EA EA EA AA EA EA EA EA AA EA EA EA EA AA EA F2 F2 F2 AA F2 F2 F2 F2
					39 00 00 40 00 00 04 FF 5A A5 00
					39 00 00 40 00 00 03 51 04 4D
					15 00 00 40 00 00 02 60 07
					39 00 00 40 00 00 04 FF 5A A5 24
					39 00 00 40 00 00 09 AC 10 ED 0F FE 0D BB 0A 81
					39 00 00 40 00 00 09 AD 06 E9 04 4D 04 3B 03 A2
					39 00 00 40 00 00 09 AE 02 8E 01 A0 00 01 00 00
					39 00 00 40 00 00 04 FF 5A A5 4F
					15 00 00 40 00 00 02 8A 78
					39 00 00 40 00 00 04 FF 5A A5 1E
					39 00 00 40 00 00 1F 8E AA 62 EA EA EA AA EA EA EA EA AA EA EA EA EA AA EA EA EA EA AA EA EA EA EA AA EA EA EA EA
					39 00 00 40 00 00 1F 93 AA 62 EA EA EA AA EA EA EA EA AA EA EA EA EA AA EA EA EA EA AA EA EA EA EA AA EA EA EA EA
					39 00 00 40 00 00 04 FF 5A A5 4F
					15 00 00 00 00 00 02 8B 78
				];
				qcom,mdss-dsi-pwm-switch-high-bl-command = [
					39 00 00 40 00 00 04 FF 5A A5 4F
					15 00 00 40 00 00 02 88 78
					39 00 00 40 00 00 04 FF 5A A5 51
					39 00 00 40 00 00 07 C0 D6 D6 54 BE 11 01
					39 00 00 40 00 00 07 C1 78 64 64 5A 00 00
					39 00 00 40 00 00 07 C2 32 32 32 04 00 10
					39 00 00 40 00 00 04 FF 5A A5 51
					39 00 00 40 00 00 07 A0 44 44 45 3A 22 22
					39 00 00 40 00 00 07 A1 41 44 41 63 22 22
					39 00 00 40 00 00 07 A2 60 5D 5D 48 22 22
					39 00 00 40 00 00 04 FF 5A A5 52
					39 00 00 40 00 00 07 80 D6 D6 53 BC 11 01
					39 00 00 40 00 00 07 81 74 63 63 55 00 00
					39 00 00 40 00 00 07 82 2F 2F 2F 04 00 10
					39 00 00 40 00 00 04 FF 5A A5 53
					39 00 00 40 00 00 03 85 CC E3
					39 00 00 40 00 00 04 FF 5A A5 1E
					39 00 00 40 00 00 1F 8E AA 54 DC DC DC AA DC DC DC DC AA DC DC DC DC AA DC DC DC DC AA DC D0 D0 D0 AA D0 D0 D0 D0
					39 00 00 40 00 00 1F 93 AA 54 DC DC DC AA DC DC DC DC AA DC DC DC DC AA DC DC DC DC AA DC D0 D0 D0 AA D0 D0 D0 D0
					39 00 00 40 00 00 04 FF 5A A5 00
					39 00 00 40 00 00 03 51 04 4D
					15 00 00 40 00 00 02 60 0C
					39 00 00 40 00 00 04 FF 5A A5 24
					39 00 00 40 00 00 09 AC 10 ED 0F FE 0D BB 0A 81
					39 00 00 40 00 00 09 AD 06 E9 04 4D 03 A2 02 8E
					39 00 00 40 00 00 09 AE 01 A0 00 01 00 00 00 00
					39 00 00 40 00 00 04 FF 5A A5 4F
					15 00 00 40 00 00 02 8A 78
					39 00 00 40 00 00 04 FF 5A A5 01
					39 00 00 40 00 00 07 80 0C 00 00 00 10 29
					39 00 00 40 00 00 04 FF 5A A5 23
					15 00 00 40 00 00 02 AC 1A
					39 00 00 40 00 00 04 FF 5A A5 0B
					39 00 00 40 00 00 04 89 00 3F 07
					39 00 00 40 00 00 04 8A 00 05 05
					39 00 00 40 00 00 04 A8 00 0F 37
					39 00 00 40 00 00 04 A9 00 0B 1F
					39 00 00 40 00 00 04 FF 5A A5 1E
					39 00 00 40 00 00 1F 8E AA 62 EA EA EA AA EA EA EA EA AA EA EA EA EA AA EA EA EA EA AA EA EA EA EA AA EA EA EA EA
					39 00 00 40 00 00 1F 93 AA 62 EA EA EA AA EA EA EA EA AA EA EA EA EA AA EA EA EA EA AA EA EA EA EA AA EA EA EA EA
					39 00 00 40 00 00 04 FF 5A A5 4F
					15 00 00 00 00 00 02 8B 78
				];

				//qcom,panel-roi-alignment=<1080 44 1080 44 1080 44>;
				//qcom,partial-update-enabled = "single_roi";

				qcom,lm-split = <720 720>;
				qcom,mdss-dsc-slice-height = <22>;
				qcom,mdss-dsc-slice-width = <720>;
			};
			timing@wqhd_sdc_60 {
				#include "dsi-panel-AA569-P-3-A0019-common.dtsi"
				#include "dsi-panel-AA569-P-3-A0019-loading-effect.dtsi"
				cell-index = <2>;
				qcom,mdss-mdp-transfer-time-us = <6800>;
				qcom,mdss-dsi-panel-framerate = <60>;
				qcom,mdss-dsi-panel-clockrate = <1363200000>;
				qcom,mdss-dsi-panel-width = <1440>;
				qcom,mdss-dsi-panel-height = <3168>;
				qcom,mdss-dsi-h-front-porch = <64>;
				qcom,mdss-dsi-h-back-porch = <50>;
				qcom,mdss-dsi-h-pulse-width = <8>;
				qcom,mdss-dsi-h-sync-pulse = <0>;
				qcom,mdss-dsi-v-back-porch = <12>;
				qcom,mdss-dsi-v-front-porch = <16>;
				qcom,mdss-dsi-v-pulse-width = <4>;
				qcom,dsi-mode-te-width-us = <540>;

				/* Apollo vsync config, need to measure TE signal */
				oplus,apollo-panel-vsync-width = <8600>;

				qcom,mdss-dsi-timing-switch-command = [
					//60hz
					39 00 00 40 00 00 04 FF 5A A5 00
					15 00 00 40 00 00 02 60 00
					39 00 00 40 00 00 04 FF 5A A5 2D
					39 00 00 40 00 00 03 83 01 00
					15 00 00 40 00 00 02 F2 01
					39 00 00 40 00 00 04 FF 5A A5 02
					39 00 00 40 00 00 04 B0 01 80 00
					39 00 00 00 00 00 04 FF 5A A5 00
				];
				qcom,mdss-dsi-on-command = [
					/* common setting */
					39 00 00 40 00 00 04 FF 5A A5 07
					15 00 00 40 00 00 02 8A 01
					39 00 00 40 00 00 04 FF 5A A5 31
					15 00 00 40 00 00 02 D0 80
					39 00 00 40 00 00 04 FF 5A A5 08
					15 00 00 40 00 00 02 BE 01
					39 00 00 40 00 00 04 FF 5A A5 08
					15 00 00 40 00 00 02 D2 05
					15 00 00 40 00 00 02 D3 0F
					15 00 00 40 00 00 02 D4 40
					15 00 00 40 00 00 02 F5 55
					15 00 00 40 00 00 02 F6 18
					39 00 00 40 00 00 04 FF 5A A5 21
					15 00 00 40 00 00 02 A4 18
					39 00 00 40 00 00 04 FF 5A A5 1F
					39 00 00 40 00 00 19 8F 03 08 50 0E 01 00 00 00 00 00 00 00 00 00 00 00 02 0E 00 00 08 02 00 00
					39 00 00 40 00 00 04 FF 5A A5 05
					15 00 00 40 00 00 02 9E 77
					39 00 00 40 00 00 04 FF 5A A5 14
					15 00 00 40 00 00 02 80 00
					39 00 00 40 00 00 04 FF 5A A5 17
					15 00 00 40 00 00 02 A0 00
					39 00 00 40 00 00 04 FF 5A A5 13
					15 00 00 40 00 00 02 F9 5C
					39 00 00 40 00 00 04 FF 5A A5 05
					15 00 00 40 00 00 02 85 00
					39 00 00 40 00 00 04 FF 5A A5 1C
					39 00 00 40 00 00 13 E2 0A 0A 0A 1A 1A 1A 1A 1A 0A 0A 0A 04 27 12 23 09 46 45
					39 00 00 40 00 00 04 FF 5A A5 01
					15 00 00 40 00 00 02 FB 08
					39 00 00 40 00 00 04 FF 5A A5 09
					39 00 00 40 00 00 07 8E 10 82 00 00 00 00
					39 00 00 40 00 00 04 FF 5A A5 02
					39 00 00 00 00 00 03 88 C0 00
					/* spr in ap */
					39 00 00 40 00 00 04 FF 5A A5 14
					15 00 00 40 00 00 02 82 01		//SPR IN AP MODE
					39 00 00 40 00 00 04 FF 5A A5 07
					15 00 00 40 00 00 02 91 03		//CR CB SETTING
					15 00 00 40 00 00 02 8A 01         //DSC ON
					39 00 00 40 00 00 03 8B A0 21
					39 00 00 00 00 00 64 81 00 00 00 00 00 12 00 00 AB
					                     21 00 0C 60 05 A0 00 16 02 D0
					                     02 D0 01 55 01 E2 00 0A 01 4D
					                     00 3C 00 0D 04 F4 13 A3 08 00
					                     0C 00 07 10 20 00 06 0F 0F 33
					                     0E 1C 2A 38 46 54 62 69 70 77
					                     79 7B 7D 7E 00 82 11 40 19 C0
					                     22 3E 32 7C 3A BA 3A F8 3B 38
					                     3B 38 3B 76 4B 76 4B 74 4B 74
					                     5B B4 73 F4 01 00 00 00 00 00
					/* Skip frame setting */
					39 00 00 40 00 00 04 FF 5A A5 00
					15 00 00 40 00 00 02 5E 01
					15 00 00 40 00 00 02 60 00
					15 00 00 40 00 00 02 61 0D
					39 00 00 40 00 00 04 FF 5A A5 00
					15 00 00 40 00 00 02 6D 01
					39 00 00 40 00 00 04 FF 5A A5 00
					15 00 00 40 00 00 02 35 00
					15 00 00 00 00 00 02 53 20
					//60hz
					39 00 00 40 00 00 04 FF 5A A5 00
					15 00 00 40 00 00 02 60 00
					39 00 00 40 00 00 04 FF 5A A5 2D
					39 00 00 40 00 00 03 83 01 00
					15 00 00 40 00 00 02 F2 01
					39 00 00 40 00 00 04 FF 5A A5 02
					39 00 00 40 00 00 04 B0 01 80 00
					39 00 00 00 00 00 04 FF 5A A5 00
					// AP SPR
					39 00 00 40 00 00 04 FF 5A A5 02
					39 00 00 40 00 00 03 84 01 05
					// OPR mode
					39 00 00 40 00 00 04 FF 5A A5 1E
					39 00 00 40 00 00 04 98 99 AA 99
					39 00 00 40 00 00 0C 99 88 00 00 88 00 00 88 00 00 08 00
					15 00 00 40 00 00 02 A3 00
					// PeakLumin Dimming Off
					39 00 00 40 00 00 04 FF 5A A5 1E
					15 00 00 40 00 00 02 81 00
					39 00 00 00 00 00 04 FF 5A A5 00
					/* OSC Tracking */
					39 00 00 40 00 00 04 FF 5A A5 22
					39 00 00 40 00 00 08 D8 01 0C 11 10 32 19 19
					39 00 00 40 00 00 0A DC 84 94 BB 00 20 C4 A1 CC 10
					15 00 00 40 00 00 02 DD 01
					15 00 00 40 00 00 02 DE F1
					15 00 00 40 00 00 02 DF 80
					39 00 00 40 00 00 07 E0 02 00 5F 21 00 28
					39 00 00 00 00 00 04 FF 5A A5 00
					/* decreasing step setting */
					39 00 00 40 00 00 04 FF 5A A5 2D
					39 00 00 40 00 00 03 ED 05 00
					15 00 00 40 00 00 02 97 02
					15 00 00 40 00 00 02 98 03
					15 00 00 40 00 00 02 99 0B
					15 00 00 40 00 00 02 9A 17
					39 00 00 40 00 00 03 A0 00 02
					39 00 00 40 00 00 03 A1 02 00
					15 00 00 40 00 00 02 A4 02
					15 00 00 40 00 00 02 A5 02
					15 00 00 40 00 00 02 A6 08
					15 00 00 40 00 00 02 A7 11
					39 00 00 40 00 00 03 AD 00 02
					39 00 00 40 00 00 03 AE 02 00
					39 00 00 00 00 00 04 FF 5A A5 00
					/* partial update esd */
					39 00 00 40 00 00 04 FF 5A A5 08
					15 00 00 00 00 00 02 98 66

					05 00 00 00 78 00 01 11

					39 00 00 40 00 00 04 FF 5A A5 4F
					15 00 00 40 00 00 02 80 01
					39 00 00 40 00 00 04 FF 5A A5 53
					15 00 00 40 00 00 02 F0 01
					39 00 00 40 00 00 04 FF 5A A5 63
					39 00 00 40 00 00 11 F8 00 00 00 00 00 00 00 00 00 00 00 00 00 00 00 00
					39 00 00 40 00 00 11 F9 00 00 00 00 00 00 00 00 00 00 00 00 00 00 00 00
					39 00 00 40 00 00 11 FA 00 00 00 00 00 00 00 00 00 00 00 00 00 00 00 00
					39 00 00 40 00 00 04 FF 5A A5 53
					15 00 00 40 00 00 02 F0 00
					39 00 00 00 00 00 04 FF 5A A5 00
					/* ODC optimize drag shadow */
					39 00 00 40 00 00 04 FF 5A A5 49
					15 00 00 40 00 00 02 D9 03
					15 00 00 40 00 00 02 DA 1E
					15 00 00 40 00 00 02 DB FC
					15 00 00 40 00 00 02 DF 06
					39 00 00 00 00 00 04 FF 5A A5 00
					/* optimize crosstalk */
					39 00 00 40 00 00 04 FF 5A A5 5A
					39 00 00 40 00 00 04 81 07 1A 04
					39 00 00 40 00 00 04 8A F6 17 12
					39 00 00 40 00 00 04 8F 12 3A 33
					39 00 00 40 00 00 04 A5 09 1A 08
					39 00 00 40 00 00 04 B3 30 38 31
					39 00 00 40 00 00 04 C9 08 0D 06
					39 00 00 40 00 00 04 CA 03 06 03
					39 00 00 40 00 00 04 D7 2F 34 2D
					39 00 00 40 00 00 04 FF 5A A5 5B
					39 00 00 40 00 00 04 81 05 09 03
					39 00 00 40 00 00 04 83 02 0C 05
					39 00 00 40 00 00 04 93 00 01 07
					39 00 00 40 00 00 04 94 05 06 05
					39 00 00 40 00 00 04 A5 09 0C 04
					39 00 00 40 00 00 04 A7 FD 0F 04
					39 00 00 40 00 00 04 B7 02 07 07
					39 00 00 40 00 00 04 B8 05 07 06
					39 00 00 40 00 00 04 C9 05 07 02
					39 00 00 40 00 00 04 CA 00 00 00
					39 00 00 40 00 00 04 CB 02 09 FF
					39 00 00 40 00 00 04 DB 00 04 06
					39 00 00 40 00 00 04 DC 00 06 04
					39 00 00 40 00 00 04 FF 5A A5 5C
					39 00 00 40 00 00 04 81 00 03 02
					39 00 00 40 00 00 04 83 01 08 05
					39 00 00 40 00 00 04 93 FF 01 02
					39 00 00 40 00 00 04 94 FF 06 04
					39 00 00 40 00 00 04 A5 01 03 02
					39 00 00 40 00 00 04 B7 FF 01 06
					39 00 00 40 00 00 04 B8 FF 06 03
					39 00 00 00 00 00 04 FF 5A A5 00

					05 00 00 00 00 00 01 29
				];
				/* pwm */
				qcom,mdss-dsi-timming-pwm-switch-onepulse-command = [
					//1pulse code 60hz
					39 00 00 40 00 00 04 FF 5A A5 00
					15 00 00 40 00 00 02 60 0B
					39 00 00 40 00 00 04 FF 5A A5 2D
					39 00 00 40 00 00 03 8E 01 00
					15 00 00 40 00 00 02 F2 01
					39 00 00 40 00 00 04 FF 5A A5 02
					39 00 00 40 00 00 04 B0 01 80 00
					39 00 00 00 00 00 04 FF 5A A5 00
				];
				qcom,mdss-dsi-pwm-switch-mode0-command= [
					39 00 00 40 00 00 04 FF 5A A5 4F
					15 00 00 40 00 00 02 88 78
					39 00 00 40 00 00 04 FF 5A A5 01
					39 00 00 40 00 00 07 80 0C 00 00 00 10 19
					39 00 00 40 00 00 04 FF 5A A5 0B
					39 00 00 40 00 00 04 89 00 2F 17
					39 00 00 40 00 00 04 8A 00 00 05
					39 00 00 40 00 00 04 A8 00 0F 37
					39 00 00 40 00 00 04 A9 00 00 1F
					39 00 00 40 00 00 04 FF 5A A5 23
					15 00 00 40 00 00 02 AC 5A
					39 00 00 40 00 00 04 FF 5A A5 51
					39 00 00 40 00 00 07 C0 D6 D6 54 BE 11 01
					39 00 00 40 00 00 07 C1 78 64 64 5A 00 00
					39 00 00 40 00 00 07 C2 50 50 50 04 00 10
					39 00 00 40 00 00 04 FF 5A A5 51
					39 00 00 40 00 00 07 A0 5F 5F 5F 55 22 22
					39 00 00 40 00 00 07 A1 5A 5A 4E 75 22 22
					39 00 00 40 00 00 07 A2 70 6C 69 48 22 22
					39 00 00 40 00 00 04 FF 5A A5 52
					39 00 00 40 00 00 07 80 DA DA 57 C4 11 01
					39 00 00 40 00 00 07 81 7E 6A 70 5F 00 00
					39 00 00 40 00 00 07 82 55 56 54 04 00 10
					39 00 00 40 00 00 04 FF 5A A5 53
					39 00 00 40 00 00 03 85 CC E1
					39 00 00 40 00 00 04 FF 5A A5 1E
					39 00 00 40 00 00 1F 8E AA 62 EA EA EA AA EA EA EA EA AA EA EA EA EA AA EA EA EA EA AA EA F2 F2 F2 AA F2 F2 F2 F2
					39 00 00 40 00 00 1F 93 AA 62 EA EA EA AA EA EA EA EA AA EA EA EA EA AA EA EA EA EA AA EA F2 F2 F2 AA F2 F2 F2 F2
					39 00 00 40 00 00 04 FF 5A A5 24
					39 00 00 40 00 00 09 AC 10 ED 0F FE 0D BB 0A 81
					39 00 00 40 00 00 09 AD 06 E9 04 4D 04 3B 03 A2
					39 00 00 40 00 00 09 AE 02 8E 01 A0 00 01 00 00
					39 00 00 40 00 00 04 FF 5A A5 00
					15 00 00 40 00 00 02 60 00
					39 00 00 40 00 00 04 FF 5A A5 4F
					15 00 00 40 00 00 02 8A 78
					39 00 00 40 00 00 04 FF 5A A5 1E
					39 00 00 40 00 00 1F 8E AA 62 EA EA EA AA EA EA EA EA AA EA EA EA EA AA EA EA EA EA AA EA EA EA EA AA EA EA EA EA
					39 00 00 40 00 00 1F 93 AA 62 EA EA EA AA EA EA EA EA AA EA EA EA EA AA EA EA EA EA AA EA EA EA EA AA EA EA EA EA
					39 00 00 40 00 00 04 FF 5A A5 4F
					15 00 00 40 00 00 02 8A 78
					39 00 00 40 00 00 04 FF 5A A5 4F
					15 00 00 00 00 00 02 8B 78
				];
				qcom,mdss-dsi-pwm-switch-mode2-command = [
					39 00 00 40 00 00 04 FF 5A A5 4F
					15 00 00 40 00 00 02 88 78
					39 00 00 40 00 00 04 FF 5A A5 51
					39 00 00 40 00 00 07 C0 D6 D6 54 BE 11 01
					39 00 00 40 00 00 07 C1 78 64 64 5A 00 00
					39 00 00 40 00 00 07 C2 32 32 32 04 00 10
					39 00 00 40 00 00 04 FF 5A A5 51
					39 00 00 40 00 00 07 A0 44 44 45 3A 22 22
					39 00 00 40 00 00 07 A1 41 44 41 63 22 22
					39 00 00 40 00 00 07 A2 60 5D 5D 48 22 22
					39 00 00 40 00 00 04 FF 5A A5 52
					39 00 00 40 00 00 07 80 D6 D6 53 BC 11 01
					39 00 00 40 00 00 07 81 74 63 63 55 00 00
					39 00 00 40 00 00 07 82 2F 2F 2F 04 00 10
					39 00 00 40 00 00 04 FF 5A A5 53
					39 00 00 40 00 00 03 85 CC E3
					39 00 00 40 00 00 04 FF 5A A5 1E
					39 00 00 40 00 00 1F 8E AA 54 DC DC DC AA DC DC DC DC AA DC DC DC DC AA DC DC DC DC AA DC D0 D0 D0 AA D0 D0 D0 D0
					39 00 00 40 00 00 1F 93 AA 54 DC DC DC AA DC DC DC DC AA DC DC DC DC AA DC DC DC DC AA DC D0 D0 D0 AA D0 D0 D0 D0
					39 00 00 40 00 00 04 FF 5A A5 24
					39 00 00 40 00 00 09 AC 10 ED 0F FE 0D BB 0A 81
					39 00 00 40 00 00 09 AD 06 E9 04 4D 03 A2 02 8E
					39 00 00 40 00 00 09 AE 01 A0 00 01 00 00 00 00
					39 00 00 40 00 00 04 FF 5A A5 00
					15 00 00 40 00 00 02 60 0B
					39 00 00 40 00 00 04 FF 5A A5 4F
					15 00 00 40 00 00 02 8A 78
					39 00 00 40 00 00 04 FF 5A A5 01
					39 00 00 40 00 00 07 80 0C 00 00 00 10 29
					39 00 00 40 00 00 04 FF 5A A5 23
					15 00 00 40 00 00 02 AC 1A
					39 00 00 40 00 00 04 FF 5A A5 0B
					39 00 00 40 00 00 04 89 00 3F 07
					39 00 00 40 00 00 04 8A 00 05 05
					39 00 00 40 00 00 04 A8 00 0F 37
					39 00 00 40 00 00 04 A9 00 0B 1F
					39 00 00 40 00 00 04 FF 5A A5 1E
					39 00 00 40 00 00 1F 8E AA 62 EA EA EA AA EA EA EA EA AA EA EA EA EA AA EA EA EA EA AA EA EA EA EA AA EA EA EA EA
					39 00 00 40 00 00 1F 93 AA 62 EA EA EA AA EA EA EA EA AA EA EA EA EA AA EA EA EA EA AA EA EA EA EA AA EA EA EA EA
					39 00 00 40 00 00 04 FF 5A A5 4F
					15 00 00 40 00 00 02 8A 78
					39 00 00 40 00 00 04 FF 5A A5 4F
					15 00 00 00 00 00 02 8B 78
				];
				qcom,mdss-dsi-pwm-switch-mode2-panel-on-command = [
					39 00 00 40 00 00 04 FF 5A A5 4F
					15 00 00 40 00 00 02 88 78
					39 00 00 40 00 00 04 FF 5A A5 51
					39 00 00 40 00 00 07 C0 D6 D6 54 BE 11 01
					39 00 00 40 00 00 07 C1 78 64 64 5A 00 00
					39 00 00 40 00 00 07 C2 32 32 32 04 00 10
					39 00 00 40 00 00 04 FF 5A A5 51
					39 00 00 40 00 00 07 A0 44 44 45 3A 22 22
					39 00 00 40 00 00 07 A1 41 44 41 63 22 22
					39 00 00 40 00 00 07 A2 60 5D 5D 48 22 22
					39 00 00 40 00 00 04 FF 5A A5 52
					39 00 00 40 00 00 07 80 D6 D6 53 BC 11 01
					39 00 00 40 00 00 07 81 74 63 63 55 00 00
					39 00 00 40 00 00 07 82 2F 2F 2F 04 00 10
					39 00 00 40 00 00 04 FF 5A A5 53
					39 00 00 40 00 00 03 85 CC E3
					39 00 00 40 00 00 04 FF 5A A5 1E
					39 00 00 40 00 00 1F 8E AA 54 DC DC DC AA DC DC DC DC AA DC DC DC DC AA DC DC DC DC AA DC D0 D0 D0 AA D0 D0 D0 D0
					39 00 00 40 00 00 1F 93 AA 54 DC DC DC AA DC DC DC DC AA DC DC DC DC AA DC DC DC DC AA DC D0 D0 D0 AA D0 D0 D0 D0
					39 00 00 40 00 00 04 FF 5A A5 24
					39 00 00 40 00 00 09 AC 10 ED 0F FE 0D BB 0A 81
					39 00 00 40 00 00 09 AD 06 E9 04 4D 03 A2 02 8E
					39 00 00 40 00 00 09 AE 01 A0 00 01 00 00 00 00
					39 00 00 40 00 00 04 FF 5A A5 00
					15 00 00 40 00 00 02 60 0B
					39 00 00 40 00 00 04 FF 5A A5 4F
					15 00 00 40 00 00 02 8A 78
					39 00 00 40 00 00 04 FF 5A A5 01
					39 00 00 40 00 00 07 80 0C 00 00 00 10 29
					39 00 00 40 00 00 04 FF 5A A5 23
					15 00 00 40 00 00 02 AC 1A
					39 00 00 40 00 00 04 FF 5A A5 0B
					39 00 00 40 00 00 04 89 00 3F 07
					39 00 00 40 00 00 04 8A 00 05 05
					39 00 00 40 00 00 04 A8 00 0F 37
					39 00 00 40 00 00 04 A9 00 0B 1F
					39 00 00 40 00 00 04 FF 5A A5 1E
					39 00 00 40 00 00 1F 8E AA 62 EA EA EA AA EA EA EA EA AA EA EA EA EA AA EA EA EA EA AA EA EA EA EA AA EA EA EA EA
					39 00 00 40 00 00 1F 93 AA 62 EA EA EA AA EA EA EA EA AA EA EA EA EA AA EA EA EA EA AA EA EA EA EA AA EA EA EA EA
					39 00 00 40 00 00 04 FF 5A A5 4F
					15 00 00 40 00 00 02 8A 78
					39 00 00 40 00 00 04 FF 5A A5 4F
					15 00 00 00 11 00 02 8B 78
				];
				qcom,mdss-dsi-pwm-switch-low-bl-command = [
					39 00 00 40 00 00 04 FF 5A A5 4F
					15 00 00 40 00 00 02 88 78
					39 00 00 40 00 00 04 FF 5A A5 01
					39 00 00 40 00 00 07 80 0C 00 00 00 10 19
					39 00 00 40 00 00 04 FF 5A A5 0B
					39 00 00 40 00 00 04 89 00 2F 17
					39 00 00 40 00 00 04 8A 00 00 05
					39 00 00 40 00 00 04 A8 00 0F 37
					39 00 00 40 00 00 04 A9 00 00 1F
					39 00 00 40 00 00 04 FF 5A A5 23
					15 00 00 40 00 00 02 AC 5A
					39 00 00 40 00 00 04 FF 5A A5 51
					39 00 00 40 00 00 07 C0 D6 D6 54 BE 11 01
					39 00 00 40 00 00 07 C1 78 64 64 5A 00 00
					39 00 00 40 00 00 07 C2 50 50 50 04 00 10
					39 00 00 40 00 00 04 FF 5A A5 51
					39 00 00 40 00 00 07 A0 5F 5F 5F 55 22 22
					39 00 00 40 00 00 07 A1 5A 5A 4E 75 22 22
					39 00 00 40 00 00 07 A2 70 6C 69 48 22 22
					39 00 00 40 00 00 04 FF 5A A5 52
					39 00 00 40 00 00 07 80 DA DA 57 C4 11 01
					39 00 00 40 00 00 07 81 7E 6A 70 5F 00 00
					39 00 00 40 00 00 07 82 55 56 54 04 00 10
					39 00 00 40 00 00 04 FF 5A A5 53
					39 00 00 40 00 00 03 85 CC E1
					39 00 00 40 00 00 04 FF 5A A5 1E
					39 00 00 40 00 00 1F 8E AA 62 EA EA EA AA EA EA EA EA AA EA EA EA EA AA EA EA EA EA AA EA F2 F2 F2 AA F2 F2 F2 F2
					39 00 00 40 00 00 1F 93 AA 62 EA EA EA AA EA EA EA EA AA EA EA EA EA AA EA EA EA EA AA EA F2 F2 F2 AA F2 F2 F2 F2
					39 00 00 40 00 00 04 FF 5A A5 00
					39 00 00 40 00 00 03 51 04 4D
					15 00 00 40 00 00 02 60 00
					39 00 00 40 00 00 04 FF 5A A5 24
					39 00 00 40 00 00 09 AC 10 ED 0F FE 0D BB 0A 81
					39 00 00 40 00 00 09 AD 06 E9 04 4D 04 3B 03 A2
					39 00 00 40 00 00 09 AE 02 8E 01 A0 00 01 00 00
					39 00 00 40 00 00 04 FF 5A A5 4F
					15 00 00 40 00 00 02 8A 78
					39 00 00 40 00 00 04 FF 5A A5 1E
					39 00 00 40 00 00 1F 8E AA 62 EA EA EA AA EA EA EA EA AA EA EA EA EA AA EA EA EA EA AA EA EA EA EA AA EA EA EA EA
					39 00 00 40 00 00 1F 93 AA 62 EA EA EA AA EA EA EA EA AA EA EA EA EA AA EA EA EA EA AA EA EA EA EA AA EA EA EA EA
					39 00 00 40 00 00 04 FF 5A A5 4F
					15 00 00 00 00 00 02 8B 78
				];
				qcom,mdss-dsi-pwm-switch-high-bl-command = [
					39 00 00 40 00 00 04 FF 5A A5 4F
					15 00 00 40 00 00 02 88 78
					39 00 00 40 00 00 04 FF 5A A5 51
					39 00 00 40 00 00 07 C0 D6 D6 54 BE 11 01
					39 00 00 40 00 00 07 C1 78 64 64 5A 00 00
					39 00 00 40 00 00 07 C2 32 32 32 04 00 10
					39 00 00 40 00 00 04 FF 5A A5 51
					39 00 00 40 00 00 07 A0 44 44 45 3A 22 22
					39 00 00 40 00 00 07 A1 41 44 41 63 22 22
					39 00 00 40 00 00 07 A2 60 5D 5D 48 22 22
					39 00 00 40 00 00 04 FF 5A A5 52
					39 00 00 40 00 00 07 80 D6 D6 53 BC 11 01
					39 00 00 40 00 00 07 81 74 63 63 55 00 00
					39 00 00 40 00 00 07 82 2F 2F 2F 04 00 10
					39 00 00 40 00 00 04 FF 5A A5 53
					39 00 00 40 00 00 03 85 CC E3
					39 00 00 40 00 00 04 FF 5A A5 1E
					39 00 00 40 00 00 1F 8E AA 54 DC DC DC AA DC DC DC DC AA DC DC DC DC AA DC DC DC DC AA DC D0 D0 D0 AA D0 D0 D0 D0
					39 00 00 40 00 00 1F 93 AA 54 DC DC DC AA DC DC DC DC AA DC DC DC DC AA DC DC DC DC AA DC D0 D0 D0 AA D0 D0 D0 D0
					39 00 00 40 00 00 04 FF 5A A5 00
					39 00 00 40 00 00 03 51 04 4D
					15 00 00 40 00 00 02 60 0B
					39 00 00 40 00 00 04 FF 5A A5 24
					39 00 00 40 00 00 09 AC 10 ED 0F FE 0D BB 0A 81
					39 00 00 40 00 00 09 AD 06 E9 04 4D 03 A2 02 8E
					39 00 00 40 00 00 09 AE 01 A0 00 01 00 00 00 00
					39 00 00 40 00 00 04 FF 5A A5 4F
					15 00 00 40 00 00 02 8A 78
					39 00 00 40 00 00 04 FF 5A A5 01
					39 00 00 40 00 00 07 80 0C 00 00 00 10 29
					39 00 00 40 00 00 04 FF 5A A5 23
					15 00 00 40 00 00 02 AC 1A
					39 00 00 40 00 00 04 FF 5A A5 0B
					39 00 00 40 00 00 04 89 00 3F 07
					39 00 00 40 00 00 04 8A 00 05 05
					39 00 00 40 00 00 04 A8 00 0F 37
					39 00 00 40 00 00 04 A9 00 0B 1F
					39 00 00 40 00 00 04 FF 5A A5 1E
					39 00 00 40 00 00 1F 8E AA 62 EA EA EA AA EA EA EA EA AA EA EA EA EA AA EA EA EA EA AA EA EA EA EA AA EA EA EA EA
					39 00 00 40 00 00 1F 93 AA 62 EA EA EA AA EA EA EA EA AA EA EA EA EA AA EA EA EA EA AA EA EA EA EA AA EA EA EA EA
					39 00 00 40 00 00 04 FF 5A A5 4F
					15 00 00 00 00 00 02 8B 78
				];

				//qcom,panel-roi-alignment=<1080 44 1080 44 1080 44>;
				//qcom,partial-update-enabled = "single_roi";

				qcom,lm-split = <720 720>;
				qcom,mdss-dsc-slice-height = <22>;
				qcom,mdss-dsc-slice-width = <720>;
				oplus,apollo-panel-async-bl-delay = <9000>;
			};
			timing@wqhd_oplus_120 {
				#include "dsi-panel-AA569-P-3-A0019-common.dtsi"
				#include "dsi-panel-AA569-P-3-A0019-loading-effect.dtsi"
				cell-index = <3>;
				qcom,mdss-mdp-transfer-time-us = <6800>;
				qcom,mdss-dsi-panel-framerate = <120>;
				qcom,mdss-dsi-panel-clockrate = <1363200000>;
				qcom,mdss-dsi-panel-width = <1440>;
				qcom,mdss-dsi-panel-height = <3168>;
				qcom,mdss-dsi-h-front-porch = <64>;
				qcom,mdss-dsi-h-back-porch = <50>;
				qcom,mdss-dsi-h-pulse-width = <8>;
				qcom,mdss-dsi-h-sync-pulse = <0>;
				qcom,mdss-dsi-v-back-porch = <12>;
				qcom,mdss-dsi-v-front-porch = <16>;
				qcom,mdss-dsi-v-pulse-width = <4>;
				qcom,dsi-mode-te-width-us = <540>;

				qcom,mdss-dsi-timing-switch-command = [
					//OA-120Hz
					39 00 00 40 00 00 04 FF 5A A5 00
					15 00 00 40 00 00 02 60 00
					39 00 00 40 00 00 04 FF 5A A5 2D
					39 00 00 40 00 00 03 83 00 00
					15 00 00 40 00 00 02 F2 00
					39 00 00 40 00 00 04 FF 5A A5 02
					39 00 00 40 00 00 04 B0 01 88 00
					39 00 00 00 00 00 04 FF 5A A5 00
				];
				qcom,mdss-dsi-on-command = [
					/* common setting */
					39 00 00 40 00 00 04 FF 5A A5 07
					15 00 00 40 00 00 02 8A 01
					39 00 00 40 00 00 04 FF 5A A5 31
					15 00 00 40 00 00 02 D0 80
					39 00 00 40 00 00 04 FF 5A A5 08
					15 00 00 40 00 00 02 BE 01
					39 00 00 40 00 00 04 FF 5A A5 08
					15 00 00 40 00 00 02 D2 05
					15 00 00 40 00 00 02 D3 0F
					15 00 00 40 00 00 02 D4 40
					15 00 00 40 00 00 02 F5 55
					15 00 00 40 00 00 02 F6 18
					39 00 00 40 00 00 04 FF 5A A5 21
					15 00 00 40 00 00 02 A4 18
					39 00 00 40 00 00 04 FF 5A A5 1F
					39 00 00 40 00 00 19 8F 03 08 50 0E 01 00 00 00 00 00 00 00 00 00 00 00 02 0E 00 00 08 02 00 00
					39 00 00 40 00 00 04 FF 5A A5 05
					15 00 00 40 00 00 02 9E 77
					39 00 00 40 00 00 04 FF 5A A5 14
					15 00 00 40 00 00 02 80 00
					39 00 00 40 00 00 04 FF 5A A5 17
					15 00 00 40 00 00 02 A0 00
					39 00 00 40 00 00 04 FF 5A A5 13
					15 00 00 40 00 00 02 F9 5C
					39 00 00 40 00 00 04 FF 5A A5 05
					15 00 00 40 00 00 02 85 00
					39 00 00 40 00 00 04 FF 5A A5 1C
					39 00 00 40 00 00 13 E2 0A 0A 0A 1A 1A 1A 1A 1A 0A 0A 0A 04 27 12 23 09 46 45
					39 00 00 40 00 00 04 FF 5A A5 01
					15 00 00 40 00 00 02 FB 08
					39 00 00 40 00 00 04 FF 5A A5 09
					39 00 00 40 00 00 07 8E 10 82 00 00 00 00
					39 00 00 40 00 00 04 FF 5A A5 02
					39 00 00 00 00 00 03 88 C0 00
					/* spr in ap */
					39 00 00 40 00 00 04 FF 5A A5 14
					15 00 00 40 00 00 02 82 01		//SPR IN AP MODE
					39 00 00 40 00 00 04 FF 5A A5 07
					15 00 00 40 00 00 02 91 03		//CR CB SETTING
					15 00 00 40 00 00 02 8A 01         //DSC ON
					39 00 00 40 00 00 03 8B A0 21
					39 00 00 00 00 00 64 81 00 00 00 00 00 12 00 00 AB
					                     21 00 0C 60 05 A0 00 16 02 D0
					                     02 D0 01 55 01 E2 00 0A 01 4D
					                     00 3C 00 0D 04 F4 13 A3 08 00
					                     0C 00 07 10 20 00 06 0F 0F 33
					                     0E 1C 2A 38 46 54 62 69 70 77
					                     79 7B 7D 7E 00 82 11 40 19 C0
					                     22 3E 32 7C 3A BA 3A F8 3B 38
					                     3B 38 3B 76 4B 76 4B 74 4B 74
					                     5B B4 73 F4 01 00 00 00 00 00
					/* Skip frame setting */
					39 00 00 40 00 00 04 FF 5A A5 00
					15 00 00 40 00 00 02 5E 01
					15 00 00 40 00 00 02 60 00
					15 00 00 40 00 00 02 61 0D
					39 00 00 40 00 00 04 FF 5A A5 00
					15 00 00 40 00 00 02 6D 01
					39 00 00 40 00 00 04 FF 5A A5 00
					15 00 00 40 00 00 02 35 00
					15 00 00 00 00 00 02 53 20
					//OA-120Hz
					39 00 00 40 00 00 04 FF 5A A5 00
					15 00 00 40 00 00 02 60 00
					39 00 00 40 00 00 04 FF 5A A5 2D
					39 00 00 40 00 00 03 83 00 00
					15 00 00 40 00 00 02 F2 00
					39 00 00 40 00 00 04 FF 5A A5 02
					39 00 00 40 00 00 04 B0 01 88 00
					39 00 00 00 00 00 04 FF 5A A5 00
					// AP SPR
					39 00 00 40 00 00 04 FF 5A A5 02
					39 00 00 40 00 00 03 84 01 05
					// OPR mode
					39 00 00 40 00 00 04 FF 5A A5 1E
					39 00 00 40 00 00 04 98 99 AA 99
					39 00 00 40 00 00 0C 99 88 00 00 88 00 00 88 00 00 08 00
					15 00 00 40 00 00 02 A3 00
					// PeakLumin Dimming Off
					39 00 00 40 00 00 04 FF 5A A5 1E
					15 00 00 40 00 00 02 81 00
					39 00 00 00 00 00 04 FF 5A A5 00
					/* OSC Tracking */
					39 00 00 40 00 00 04 FF 5A A5 22
					39 00 00 40 00 00 08 D8 01 0C 11 10 32 19 19
					39 00 00 40 00 00 0A DC 84 94 BB 00 20 C4 A1 CC 10
					15 00 00 40 00 00 02 DD 01
					15 00 00 40 00 00 02 DE F1
					15 00 00 40 00 00 02 DF 80
					39 00 00 40 00 00 07 E0 02 00 5F 21 00 28
					39 00 00 00 00 00 04 FF 5A A5 00
					/* decreasing step setting */
					39 00 00 40 00 00 04 FF 5A A5 2D
					39 00 00 40 00 00 03 ED 05 00
					15 00 00 40 00 00 02 97 02
					15 00 00 40 00 00 02 98 03
					15 00 00 40 00 00 02 99 0B
					15 00 00 40 00 00 02 9A 17
					39 00 00 40 00 00 03 A0 00 02
					39 00 00 40 00 00 03 A1 02 00
					15 00 00 40 00 00 02 A4 02
					15 00 00 40 00 00 02 A5 02
					15 00 00 40 00 00 02 A6 08
					15 00 00 40 00 00 02 A7 11
					39 00 00 40 00 00 03 AD 00 02
					39 00 00 40 00 00 03 AE 02 00
					39 00 00 00 00 00 04 FF 5A A5 00
					/* partial update esd */
					39 00 00 40 00 00 04 FF 5A A5 08
					15 00 00 00 00 00 02 98 66

					05 00 00 00 78 00 01 11

					39 00 00 40 00 00 04 FF 5A A5 4F
					15 00 00 40 00 00 02 80 01
					39 00 00 40 00 00 04 FF 5A A5 53
					15 00 00 40 00 00 02 F0 01
					39 00 00 40 00 00 04 FF 5A A5 63
					39 00 00 40 00 00 11 F8 00 00 00 00 00 00 00 00 00 00 00 00 00 00 00 00
					39 00 00 40 00 00 11 F9 00 00 00 00 00 00 00 00 00 00 00 00 00 00 00 00
					39 00 00 40 00 00 11 FA 00 00 00 00 00 00 00 00 00 00 00 00 00 00 00 00
					39 00 00 40 00 00 04 FF 5A A5 53
					15 00 00 40 00 00 02 F0 00
					39 00 00 00 00 00 04 FF 5A A5 00
					/* ODC optimize drag shadow */
					39 00 00 40 00 00 04 FF 5A A5 49
					15 00 00 40 00 00 02 D9 03
					15 00 00 40 00 00 02 DA 1E
					15 00 00 40 00 00 02 DB FC
					15 00 00 40 00 00 02 DF 06
					39 00 00 00 00 00 04 FF 5A A5 00
					/* optimize crosstalk */
					39 00 00 40 00 00 04 FF 5A A5 5A
					39 00 00 40 00 00 04 81 07 1A 04
					39 00 00 40 00 00 04 8A F6 17 12
					39 00 00 40 00 00 04 8F 12 3A 33
					39 00 00 40 00 00 04 A5 09 1A 08
					39 00 00 40 00 00 04 B3 30 38 31
					39 00 00 40 00 00 04 C9 08 0D 06
					39 00 00 40 00 00 04 CA 03 06 03
					39 00 00 40 00 00 04 D7 2F 34 2D
					39 00 00 40 00 00 04 FF 5A A5 5B
					39 00 00 40 00 00 04 81 05 09 03
					39 00 00 40 00 00 04 83 02 0C 05
					39 00 00 40 00 00 04 93 00 01 07
					39 00 00 40 00 00 04 94 05 06 05
					39 00 00 40 00 00 04 A5 09 0C 04
					39 00 00 40 00 00 04 A7 FD 0F 04
					39 00 00 40 00 00 04 B7 02 07 07
					39 00 00 40 00 00 04 B8 05 07 06
					39 00 00 40 00 00 04 C9 05 07 02
					39 00 00 40 00 00 04 CA 00 00 00
					39 00 00 40 00 00 04 CB 02 09 FF
					39 00 00 40 00 00 04 DB 00 04 06
					39 00 00 40 00 00 04 DC 00 06 04
					39 00 00 40 00 00 04 FF 5A A5 5C
					39 00 00 40 00 00 04 81 00 03 02
					39 00 00 40 00 00 04 83 01 08 05
					39 00 00 40 00 00 04 93 FF 01 02
					39 00 00 40 00 00 04 94 FF 06 04
					39 00 00 40 00 00 04 A5 01 03 02
					39 00 00 40 00 00 04 B7 FF 01 06
					39 00 00 40 00 00 04 B8 FF 06 03
					39 00 00 00 00 00 04 FF 5A A5 00

					05 00 00 00 00 00 01 29
				];
				/* pwm */
				qcom,mdss-dsi-timming-pwm-switch-onepulse-command = [
					//1pulse code 120hz
					39 00 00 40 00 00 04 FF 5A A5 00
					15 00 00 40 00 00 02 60 0B
					39 00 00 40 00 00 04 FF 5A A5 2D
					39 00 00 40 00 00 03 8E 00 00
					15 00 00 40 00 00 02 F2 00
					39 00 00 40 00 00 04 FF 5A A5 02
					39 00 00 40 00 00 04 B0 01 88 00
					39 00 00 00 00 00 04 FF 5A A5 00
				];
				qcom,mdss-dsi-pwm-switch-mode0-command= [
					39 00 00 40 00 00 04 FF 5A A5 4F
					15 00 00 40 00 00 02 88 78
					39 00 00 40 00 00 04 FF 5A A5 01
					39 00 00 40 00 00 07 80 0C 00 00 00 10 19
					39 00 00 40 00 00 04 FF 5A A5 0B
					39 00 00 40 00 00 04 89 00 2F 17
					39 00 00 40 00 00 04 8A 00 00 05
					39 00 00 40 00 00 04 A8 00 0F 37
					39 00 00 40 00 00 04 A9 00 00 1F
					39 00 00 40 00 00 04 FF 5A A5 23
					15 00 00 40 00 00 02 AC 5A
					39 00 00 40 00 00 04 FF 5A A5 51
					39 00 00 40 00 00 07 C0 D6 D6 54 BE 11 01
					39 00 00 40 00 00 07 C1 78 64 64 5A 00 00
					39 00 00 40 00 00 07 C2 50 50 50 04 00 10
					39 00 00 40 00 00 04 FF 5A A5 51
					39 00 00 40 00 00 07 A0 5F 5F 5F 55 22 22
					39 00 00 40 00 00 07 A1 5A 5A 4E 75 22 22
					39 00 00 40 00 00 07 A2 70 6C 69 48 22 22
					39 00 00 40 00 00 04 FF 5A A5 52
					39 00 00 40 00 00 07 80 DA DA 57 C4 11 01
					39 00 00 40 00 00 07 81 7E 6A 70 5F 00 00
					39 00 00 40 00 00 07 82 55 56 54 04 00 10
					39 00 00 40 00 00 04 FF 5A A5 53
					39 00 00 40 00 00 03 85 CC E1
					39 00 00 40 00 00 04 FF 5A A5 1E
					39 00 00 40 00 00 1F 8E AA 62 EA EA EA AA EA EA EA EA AA EA EA EA EA AA EA EA EA EA AA EA F2 F2 F2 AA F2 F2 F2 F2
					39 00 00 40 00 00 1F 93 AA 62 EA EA EA AA EA EA EA EA AA EA EA EA EA AA EA EA EA EA AA EA F2 F2 F2 AA F2 F2 F2 F2
					39 00 00 40 00 00 04 FF 5A A5 24
					39 00 00 40 00 00 09 AC 10 ED 0F FE 0D BB 0A 81
					39 00 00 40 00 00 09 AD 06 E9 04 4D 04 3B 03 A2
					39 00 00 40 00 00 09 AE 02 8E 01 A0 00 01 00 00
					39 00 00 40 00 00 04 FF 5A A5 00
					15 00 00 40 00 00 02 60 00
					39 00 00 40 00 00 04 FF 5A A5 4F
					15 00 00 40 00 00 02 8A 78
					39 00 00 40 00 00 04 FF 5A A5 1E
					39 00 00 40 00 00 1F 8E AA 62 EA EA EA AA EA EA EA EA AA EA EA EA EA AA EA EA EA EA AA EA EA EA EA AA EA EA EA EA
					39 00 00 40 00 00 1F 93 AA 62 EA EA EA AA EA EA EA EA AA EA EA EA EA AA EA EA EA EA AA EA EA EA EA AA EA EA EA EA
					39 00 00 40 00 00 04 FF 5A A5 4F
					15 00 00 40 00 00 02 8A 78
					39 00 00 40 00 00 04 FF 5A A5 4F
					15 00 00 00 00 00 02 8B 78
				];
				qcom,mdss-dsi-pwm-switch-mode2-command = [
					39 00 00 40 00 00 04 FF 5A A5 4F
					15 00 00 40 00 00 02 88 78
					39 00 00 40 00 00 04 FF 5A A5 51
					39 00 00 40 00 00 07 C0 D6 D6 54 BE 11 01
					39 00 00 40 00 00 07 C1 78 64 64 5A 00 00
					39 00 00 40 00 00 07 C2 32 32 32 04 00 10
					39 00 00 40 00 00 04 FF 5A A5 51
					39 00 00 40 00 00 07 A0 44 44 45 3A 22 22
					39 00 00 40 00 00 07 A1 41 44 41 63 22 22
					39 00 00 40 00 00 07 A2 60 5D 5D 48 22 22
					39 00 00 40 00 00 04 FF 5A A5 52
					39 00 00 40 00 00 07 80 D6 D6 53 BC 11 01
					39 00 00 40 00 00 07 81 74 63 63 55 00 00
					39 00 00 40 00 00 07 82 2F 2F 2F 04 00 10
					39 00 00 40 00 00 04 FF 5A A5 53
					39 00 00 40 00 00 03 85 CC E3
					39 00 00 40 00 00 04 FF 5A A5 1E
					39 00 00 40 00 00 1F 8E AA 54 DC DC DC AA DC DC DC DC AA DC DC DC DC AA DC DC DC DC AA DC D0 D0 D0 AA D0 D0 D0 D0
					39 00 00 40 00 00 1F 93 AA 54 DC DC DC AA DC DC DC DC AA DC DC DC DC AA DC DC DC DC AA DC D0 D0 D0 AA D0 D0 D0 D0
					39 00 00 40 00 00 04 FF 5A A5 24
					39 00 00 40 00 00 09 AC 10 ED 0F FE 0D BB 0A 81
					39 00 00 40 00 00 09 AD 06 E9 04 4D 03 A2 02 8E
					39 00 00 40 00 00 09 AE 01 A0 00 01 00 00 00 00
					39 00 00 40 00 00 04 FF 5A A5 00
					15 00 00 40 00 00 02 60 0B
					39 00 00 40 00 00 04 FF 5A A5 4F
					15 00 00 40 00 00 02 8A 78
					39 00 00 40 00 00 04 FF 5A A5 01
					39 00 00 40 00 00 07 80 0C 00 00 00 10 29
					39 00 00 40 00 00 04 FF 5A A5 23
					15 00 00 40 00 00 02 AC 1A
					39 00 00 40 00 00 04 FF 5A A5 0B
					39 00 00 40 00 00 04 89 00 3F 07
					39 00 00 40 00 00 04 8A 00 05 05
					39 00 00 40 00 00 04 A8 00 0F 37
					39 00 00 40 00 00 04 A9 00 0B 1F
					39 00 00 40 00 00 04 FF 5A A5 1E
					39 00 00 40 00 00 1F 8E AA 62 EA EA EA AA EA EA EA EA AA EA EA EA EA AA EA EA EA EA AA EA EA EA EA AA EA EA EA EA
					39 00 00 40 00 00 1F 93 AA 62 EA EA EA AA EA EA EA EA AA EA EA EA EA AA EA EA EA EA AA EA EA EA EA AA EA EA EA EA
					39 00 00 40 00 00 04 FF 5A A5 4F
					15 00 00 40 00 00 02 8A 78
					39 00 00 40 00 00 04 FF 5A A5 4F
					15 00 00 00 00 00 02 8B 78
				];
				qcom,mdss-dsi-pwm-switch-mode2-panel-on-command = [
					39 00 00 40 00 00 04 FF 5A A5 4F
					15 00 00 40 00 00 02 88 78
					39 00 00 40 00 00 04 FF 5A A5 51
					39 00 00 40 00 00 07 C0 D6 D6 54 BE 11 01
					39 00 00 40 00 00 07 C1 78 64 64 5A 00 00
					39 00 00 40 00 00 07 C2 32 32 32 04 00 10
					39 00 00 40 00 00 04 FF 5A A5 51
					39 00 00 40 00 00 07 A0 44 44 45 3A 22 22
					39 00 00 40 00 00 07 A1 41 44 41 63 22 22
					39 00 00 40 00 00 07 A2 60 5D 5D 48 22 22
					39 00 00 40 00 00 04 FF 5A A5 52
					39 00 00 40 00 00 07 80 D6 D6 53 BC 11 01
					39 00 00 40 00 00 07 81 74 63 63 55 00 00
					39 00 00 40 00 00 07 82 2F 2F 2F 04 00 10
					39 00 00 40 00 00 04 FF 5A A5 53
					39 00 00 40 00 00 03 85 CC E3
					39 00 00 40 00 00 04 FF 5A A5 1E
					39 00 00 40 00 00 1F 8E AA 54 DC DC DC AA DC DC DC DC AA DC DC DC DC AA DC DC DC DC AA DC D0 D0 D0 AA D0 D0 D0 D0
					39 00 00 40 00 00 1F 93 AA 54 DC DC DC AA DC DC DC DC AA DC DC DC DC AA DC DC DC DC AA DC D0 D0 D0 AA D0 D0 D0 D0
					39 00 00 40 00 00 04 FF 5A A5 24
					39 00 00 40 00 00 09 AC 10 ED 0F FE 0D BB 0A 81
					39 00 00 40 00 00 09 AD 06 E9 04 4D 03 A2 02 8E
					39 00 00 40 00 00 09 AE 01 A0 00 01 00 00 00 00
					39 00 00 40 00 00 04 FF 5A A5 00
					15 00 00 40 00 00 02 60 0B
					39 00 00 40 00 00 04 FF 5A A5 4F
					15 00 00 40 00 00 02 8A 78
					39 00 00 40 00 00 04 FF 5A A5 01
					39 00 00 40 00 00 07 80 0C 00 00 00 10 29
					39 00 00 40 00 00 04 FF 5A A5 23
					15 00 00 40 00 00 02 AC 1A
					39 00 00 40 00 00 04 FF 5A A5 0B
					39 00 00 40 00 00 04 89 00 3F 07
					39 00 00 40 00 00 04 8A 00 05 05
					39 00 00 40 00 00 04 A8 00 0F 37
					39 00 00 40 00 00 04 A9 00 0B 1F
					39 00 00 40 00 00 04 FF 5A A5 1E
					39 00 00 40 00 00 1F 8E AA 62 EA EA EA AA EA EA EA EA AA EA EA EA EA AA EA EA EA EA AA EA EA EA EA AA EA EA EA EA
					39 00 00 40 00 00 1F 93 AA 62 EA EA EA AA EA EA EA EA AA EA EA EA EA AA EA EA EA EA AA EA EA EA EA AA EA EA EA EA
					39 00 00 40 00 00 04 FF 5A A5 4F
					15 00 00 40 00 00 02 8A 78
					39 00 00 40 00 00 04 FF 5A A5 4F
					15 00 00 00 09 00 02 8B 78
				];
				qcom,mdss-dsi-pwm-switch-low-bl-command = [
					39 00 00 40 00 00 04 FF 5A A5 4F
					15 00 00 40 00 00 02 88 78
					39 00 00 40 00 00 04 FF 5A A5 01
					39 00 00 40 00 00 07 80 0C 00 00 00 10 19
					39 00 00 40 00 00 04 FF 5A A5 0B
					39 00 00 40 00 00 04 89 00 2F 17
					39 00 00 40 00 00 04 8A 00 00 05
					39 00 00 40 00 00 04 A8 00 0F 37
					39 00 00 40 00 00 04 A9 00 00 1F
					39 00 00 40 00 00 04 FF 5A A5 23
					15 00 00 40 00 00 02 AC 5A
					39 00 00 40 00 00 04 FF 5A A5 51
					39 00 00 40 00 00 07 C0 D6 D6 54 BE 11 01
					39 00 00 40 00 00 07 C1 78 64 64 5A 00 00
					39 00 00 40 00 00 07 C2 50 50 50 04 00 10
					39 00 00 40 00 00 04 FF 5A A5 51
					39 00 00 40 00 00 07 A0 5F 5F 5F 55 22 22
					39 00 00 40 00 00 07 A1 5A 5A 4E 75 22 22
					39 00 00 40 00 00 07 A2 70 6C 69 48 22 22
					39 00 00 40 00 00 04 FF 5A A5 52
					39 00 00 40 00 00 07 80 DA DA 57 C4 11 01
					39 00 00 40 00 00 07 81 7E 6A 70 5F 00 00
					39 00 00 40 00 00 07 82 55 56 54 04 00 10
					39 00 00 40 00 00 04 FF 5A A5 53
					39 00 00 40 00 00 03 85 CC E1
					39 00 00 40 00 00 04 FF 5A A5 1E
					39 00 00 40 00 00 1F 8E AA 62 EA EA EA AA EA EA EA EA AA EA EA EA EA AA EA EA EA EA AA EA F2 F2 F2 AA F2 F2 F2 F2
					39 00 00 40 00 00 1F 93 AA 62 EA EA EA AA EA EA EA EA AA EA EA EA EA AA EA EA EA EA AA EA F2 F2 F2 AA F2 F2 F2 F2
					39 00 00 40 00 00 04 FF 5A A5 00
					39 00 00 40 00 00 03 51 04 4D
					15 00 00 40 00 00 02 60 00
					39 00 00 40 00 00 04 FF 5A A5 24
					39 00 00 40 00 00 09 AC 10 ED 0F FE 0D BB 0A 81
					39 00 00 40 00 00 09 AD 06 E9 04 4D 04 3B 03 A2
					39 00 00 40 00 00 09 AE 02 8E 01 A0 00 01 00 00
					39 00 00 40 00 00 04 FF 5A A5 4F
					15 00 00 40 00 00 02 8A 78
					39 00 00 40 00 00 04 FF 5A A5 1E
					39 00 00 40 00 00 1F 8E AA 62 EA EA EA AA EA EA EA EA AA EA EA EA EA AA EA EA EA EA AA EA EA EA EA AA EA EA EA EA
					39 00 00 40 00 00 1F 93 AA 62 EA EA EA AA EA EA EA EA AA EA EA EA EA AA EA EA EA EA AA EA EA EA EA AA EA EA EA EA
					39 00 00 40 00 00 04 FF 5A A5 4F
					15 00 00 00 00 00 02 8B 78
				];
				qcom,mdss-dsi-pwm-switch-high-bl-command = [
					39 00 00 40 00 00 04 FF 5A A5 4F
					15 00 00 40 00 00 02 88 78
					39 00 00 40 00 00 04 FF 5A A5 51
					39 00 00 40 00 00 07 C0 D6 D6 54 BE 11 01
					39 00 00 40 00 00 07 C1 78 64 64 5A 00 00
					39 00 00 40 00 00 07 C2 32 32 32 04 00 10
					39 00 00 40 00 00 04 FF 5A A5 51
					39 00 00 40 00 00 07 A0 44 44 45 3A 22 22
					39 00 00 40 00 00 07 A1 41 44 41 63 22 22
					39 00 00 40 00 00 07 A2 60 5D 5D 48 22 22
					39 00 00 40 00 00 04 FF 5A A5 52
					39 00 00 40 00 00 07 80 D6 D6 53 BC 11 01
					39 00 00 40 00 00 07 81 74 63 63 55 00 00
					39 00 00 40 00 00 07 82 2F 2F 2F 04 00 10
					39 00 00 40 00 00 04 FF 5A A5 53
					39 00 00 40 00 00 03 85 CC E3
					39 00 00 40 00 00 04 FF 5A A5 1E
					39 00 00 40 00 00 1F 8E AA 54 DC DC DC AA DC DC DC DC AA DC DC DC DC AA DC DC DC DC AA DC D0 D0 D0 AA D0 D0 D0 D0
					39 00 00 40 00 00 1F 93 AA 54 DC DC DC AA DC DC DC DC AA DC DC DC DC AA DC DC DC DC AA DC D0 D0 D0 AA D0 D0 D0 D0
					39 00 00 40 00 00 04 FF 5A A5 00
					39 00 00 40 00 00 03 51 04 4D
					15 00 00 40 00 00 02 60 0B
					39 00 00 40 00 00 04 FF 5A A5 24
					39 00 00 40 00 00 09 AC 10 ED 0F FE 0D BB 0A 81
					39 00 00 40 00 00 09 AD 06 E9 04 4D 03 A2 02 8E
					39 00 00 40 00 00 09 AE 01 A0 00 01 00 00 00 00
					39 00 00 40 00 00 04 FF 5A A5 4F
					15 00 00 40 00 00 02 8A 78
					39 00 00 40 00 00 04 FF 5A A5 01
					39 00 00 40 00 00 07 80 0C 00 00 00 10 29
					39 00 00 40 00 00 04 FF 5A A5 23
					15 00 00 40 00 00 02 AC 1A
					39 00 00 40 00 00 04 FF 5A A5 0B
					39 00 00 40 00 00 04 89 00 3F 07
					39 00 00 40 00 00 04 8A 00 05 05
					39 00 00 40 00 00 04 A8 00 0F 37
					39 00 00 40 00 00 04 A9 00 0B 1F
					39 00 00 40 00 00 04 FF 5A A5 1E
					39 00 00 40 00 00 1F 8E AA 62 EA EA EA AA EA EA EA EA AA EA EA EA EA AA EA EA EA EA AA EA EA EA EA AA EA EA EA EA
					39 00 00 40 00 00 1F 93 AA 62 EA EA EA AA EA EA EA EA AA EA EA EA EA AA EA EA EA EA AA EA EA EA EA AA EA EA EA EA
					39 00 00 40 00 00 04 FF 5A A5 4F
					15 00 00 00 00 00 02 8B 78
				];

				//qcom,panel-roi-alignment=<1080 44 1080 44 1080 44>;
				//qcom,partial-update-enabled = "single_roi";

				qcom,lm-split = <720 720>;
				qcom,mdss-dsc-slice-height = <22>;
				qcom,mdss-dsc-slice-width = <720>;
			};
		};
	};
};

&dsi_panel_AA569_P_3_A0019_dsc_cmd {
	qcom,ulps-enabled;
	qcom,dsi-select-clocks = "pll_byte_clk0", "pll_dsi_clk0";
	qcom,mdss-dsi-display-timings {
		timing@wqhd_sdc_120 {
			qcom,mdss-dsi-panel-phy-timings = [00 2C 0C 0C 1D 1A 0C 0C 0B 02 04 00 24 11];
			qcom,display-topology = <1 1 1>,<2 2 1>;
			qcom,default-topology-index = <1>;
			qcom,partial-update-enabled = "single_roi";
			qcom,panel-roi-alignment = <1440 22 1440 22 1440 22>;
		};
		timing@wqhd_sdc_90 {
			qcom,mdss-dsi-panel-phy-timings = [00 2C 0C 0C 1D 1A 0C 0C 0B 02 04 00 24 11];
			qcom,display-topology = <1 1 1>,<2 2 1>;
			qcom,default-topology-index = <1>;
			qcom,partial-update-enabled = "single_roi";
			qcom,panel-roi-alignment = <1440 22 1440 22 1440 22>;
		};
		timing@wqhd_sdc_60 {
			qcom,mdss-dsi-panel-phy-timings = [00 2C 0C 0C 1D 1A 0C 0C 0B 02 04 00 24 11];
			qcom,display-topology = <1 1 1>,<2 2 1>;
			qcom,default-topology-index = <1>;
			qcom,partial-update-enabled = "single_roi";
			qcom,panel-roi-alignment = <1440 22 1440 22 1440 22>;
		};
		timing@wqhd_oplus_120 {
			qcom,mdss-dsi-panel-phy-timings = [00 2C 0C 0C 1D 1A 0C 0C 0B 02 04 00 24 11];
			qcom,display-topology = <1 1 1>,<2 2 1>;
			qcom,default-topology-index = <1>;
			qcom,partial-update-enabled = "single_roi";
			qcom,panel-roi-alignment = <1440 22 1440 22 1440 22>;
		};
	};
};

&dsi_panel_AA569_P_3_A0019_dsc_cmd {
	qcom,mdss-dsi-display-timings {
		timing@wqhd_sdc_120 {
			/* SDC ADFR */
			qcom,mdss-dsi-h-sync-skew = <0>;
			oplus,adfr-min-fps-mapping-table = <120 60 30 20 10 5 1>;
			oplus,adfr-idle-off-min-fps = <20>;
			qcom,mdss-dsi-adfr-pre-switch-command = [
				39 00 00 40 00 00 04 FF 5A A5 2D
				39 00 00 40 00 00 03 83 00 00
				39 00 00 40 00 00 03 8E 00 00
				39 00 00 00 00 00 04 FF 5A A5 00
			];
			qcom,mdss-dsi-adfr-min-fps-0-command = [
				/*120Hz*/
				39 00 00 40 00 00 04 FF 5A A5 2D
				39 00 00 40 00 00 03 83 00 00
				39 00 00 00 00 00 04 FF 5A A5 00
			];
			qcom,mdss-dsi-adfr-min-fps-1-command = [
				/*60Hz*/
				39 00 00 40 00 00 04 FF 5A A5 2D
				39 00 00 40 00 00 03 83 01 00
				39 00 00 00 00 00 04 FF 5A A5 00
			];
			qcom,mdss-dsi-adfr-min-fps-2-command = [
				/*30Hz*/
				39 00 00 40 00 00 04 FF 5A A5 2D
				39 00 00 40 00 00 03 83 03 00
				39 00 00 00 00 00 04 FF 5A A5 00
			];
			qcom,mdss-dsi-adfr-min-fps-3-command = [
				/*20Hz*/
				39 00 00 40 00 00 04 FF 5A A5 2D
				39 00 00 40 00 00 03 83 05 00
				39 00 00 00 00 00 04 FF 5A A5 00
			];
			qcom,mdss-dsi-adfr-min-fps-4-command = [
				/*10Hz*/
				39 00 00 40 00 00 04 FF 5A A5 2D
				39 00 00 40 00 00 03 83 0B 00
				39 00 00 00 00 00 04 FF 5A A5 00
			];
			qcom,mdss-dsi-adfr-min-fps-5-command = [
				/*5Hz*/
				39 00 00 40 00 00 04 FF 5A A5 2D
				39 00 00 40 00 00 03 83 17 00
				39 00 00 00 00 00 04 FF 5A A5 00
			];
			qcom,mdss-dsi-adfr-min-fps-6-command = [
				/*1Hz*/
				39 00 00 40 00 00 04 FF 5A A5 2D
				39 00 00 40 00 00 03 83 77 00
				39 00 00 00 00 00 04 FF 5A A5 00
			];
			qcom,mdss-dsi-hpwm-adfr-min-fps-0-command = [
				/*120Hz*/
				39 00 00 40 00 00 04 FF 5A A5 2D
				39 00 00 40 00 00 03 83 00 00
				39 00 00 00 00 00 04 FF 5A A5 00
			];
			qcom,mdss-dsi-hpwm-adfr-min-fps-1-command = [
				/*60Hz*/
				39 00 00 40 00 00 04 FF 5A A5 2D
				39 00 00 40 00 00 03 83 01 00
				39 00 00 00 00 00 04 FF 5A A5 00
			];
			qcom,mdss-dsi-hpwm-adfr-min-fps-2-command = [
				/*30Hz*/
				39 00 00 40 00 00 04 FF 5A A5 2D
				39 00 00 40 00 00 03 83 03 00
				39 00 00 00 00 00 04 FF 5A A5 00
			];
			qcom,mdss-dsi-hpwm-adfr-min-fps-3-command = [
				/*20Hz*/
				39 00 00 40 00 00 04 FF 5A A5 2D
				39 00 00 40 00 00 03 83 05 00
				39 00 00 00 00 00 04 FF 5A A5 00
			];
			qcom,mdss-dsi-hpwm-adfr-min-fps-4-command = [
				/*10Hz*/
				39 00 00 40 00 00 04 FF 5A A5 2D
				39 00 00 40 00 00 03 83 0B 00
				39 00 00 00 00 00 04 FF 5A A5 00
			];
			qcom,mdss-dsi-hpwm-adfr-min-fps-5-command = [
				/*5Hz*/
				39 00 00 40 00 00 04 FF 5A A5 2D
				39 00 00 40 00 00 03 83 17 00
				39 00 00 00 00 00 04 FF 5A A5 00
			];
			qcom,mdss-dsi-hpwm-adfr-min-fps-6-command = [
				/*1Hz*/
				39 00 00 40 00 00 04 FF 5A A5 2D
				39 00 00 40 00 00 03 83 77 00
				39 00 00 00 00 00 04 FF 5A A5 00
			];
			qcom,mdss-dsi-bigdc-adfr-min-fps-0-command = [
				/*120Hz*/
				39 00 00 40 00 00 04 FF 5A A5 2D
				39 00 00 40 00 00 03 8E 00 00
				39 00 00 00 00 00 04 FF 5A A5 00
			];
			qcom,mdss-dsi-bigdc-adfr-min-fps-1-command = [
				/*60Hz*/
				39 00 00 40 00 00 04 FF 5A A5 2D
				39 00 00 40 00 00 03 8E 01 00
				39 00 00 00 00 00 04 FF 5A A5 00
			];
			qcom,mdss-dsi-bigdc-adfr-min-fps-2-command = [
				/*30Hz*/
				39 00 00 40 00 00 04 FF 5A A5 2D
				39 00 00 40 00 00 03 8E 03 00
				39 00 00 00 00 00 04 FF 5A A5 00
			];
			qcom,mdss-dsi-bigdc-adfr-min-fps-3-command = [
				/*20Hz*/
				39 00 00 40 00 00 04 FF 5A A5 2D
				39 00 00 40 00 00 03 8E 05 00
				39 00 00 00 00 00 04 FF 5A A5 00
			];
			qcom,mdss-dsi-bigdc-adfr-min-fps-4-command = [
				/*10Hz*/
				39 00 00 40 00 00 04 FF 5A A5 2D
				39 00 00 40 00 00 03 8E 0B 00
				39 00 00 00 00 00 04 FF 5A A5 00
			];
			qcom,mdss-dsi-bigdc-adfr-min-fps-5-command = [
				/*5Hz*/
				39 00 00 40 00 00 04 FF 5A A5 2D
				39 00 00 40 00 00 03 8E 17 00
				39 00 00 00 00 00 04 FF 5A A5 00
			];
			qcom,mdss-dsi-bigdc-adfr-min-fps-6-command = [
				/*1Hz*/
				39 00 00 40 00 00 04 FF 5A A5 2D
				39 00 00 40 00 00 03 8E 77 00
				39 00 00 00 00 00 04 FF 5A A5 00
			];

			qcom,mdss-dsi-adfr-pre-switch-command-state = "dsi_hs_mode";
			qcom,mdss-dsi-adfr-min-fps-0-command-state = "dsi_hs_mode";
			qcom,mdss-dsi-adfr-min-fps-1-command-state = "dsi_hs_mode";
			qcom,mdss-dsi-adfr-min-fps-2-command-state = "dsi_hs_mode";
			qcom,mdss-dsi-adfr-min-fps-3-command-state = "dsi_hs_mode";
			qcom,mdss-dsi-adfr-min-fps-4-command-state = "dsi_hs_mode";
			qcom,mdss-dsi-adfr-min-fps-5-command-state = "dsi_hs_mode";
			qcom,mdss-dsi-adfr-min-fps-6-command-state = "dsi_hs_mode";
			qcom,mdss-dsi-hpwm-adfr-min-fps-0-command-state = "dsi_hs_mode";
			qcom,mdss-dsi-hpwm-adfr-min-fps-1-command-state = "dsi_hs_mode";
			qcom,mdss-dsi-hpwm-adfr-min-fps-2-command-state = "dsi_hs_mode";
			qcom,mdss-dsi-hpwm-adfr-min-fps-3-command-state = "dsi_hs_mode";
			qcom,mdss-dsi-hpwm-adfr-min-fps-4-command-state = "dsi_hs_mode";
			qcom,mdss-dsi-hpwm-adfr-min-fps-5-command-state = "dsi_hs_mode";
			qcom,mdss-dsi-hpwm-adfr-min-fps-6-command-state = "dsi_hs_mode";
			qcom,mdss-dsi-bigdc-adfr-min-fps-0-command-state = "dsi_hs_mode";
			qcom,mdss-dsi-bigdc-adfr-min-fps-1-command-state = "dsi_hs_mode";
			qcom,mdss-dsi-bigdc-adfr-min-fps-2-command-state = "dsi_hs_mode";
			qcom,mdss-dsi-bigdc-adfr-min-fps-3-command-state = "dsi_hs_mode";
			qcom,mdss-dsi-bigdc-adfr-min-fps-4-command-state = "dsi_hs_mode";
			qcom,mdss-dsi-bigdc-adfr-min-fps-5-command-state = "dsi_hs_mode";
			qcom,mdss-dsi-bigdc-adfr-min-fps-6-command-state = "dsi_hs_mode";
		};
		timing@wqhd_sdc_90 {
			/* SDC ADFR */
			qcom,mdss-dsi-h-sync-skew = <0>;
			oplus,adfr-fakeframe-config = <0>;
			oplus,adfr-min-fps-mapping-table = <90 45 30 15 10 5 1>;
			qcom,mdss-dsi-adfr-pre-switch-command = [
				39 00 00 40 00 00 04 FF 5A A5 2D
				39 00 00 40 00 00 03 8A 00 00
				39 00 00 40 00 00 03 8F 00 00
				39 00 00 00 00 00 04 FF 5A A5 00
			];
			qcom,mdss-dsi-adfr-min-fps-0-command = [
				/*90Hz*/
				39 00 00 40 00 00 04 FF 5A A5 2D
				39 00 00 40 00 00 03 8A 00 00
				39 00 00 00 00 00 04 FF 5A A5 00
			];
			qcom,mdss-dsi-adfr-min-fps-1-command = [
				/*45Hz*/
				39 00 00 40 00 00 04 FF 5A A5 2D
				39 00 00 40 00 00 03 8A 01 00
				39 00 00 00 00 00 04 FF 5A A5 00
			];
			qcom,mdss-dsi-adfr-min-fps-2-command = [
				/*30Hz*/
				39 00 00 40 00 00 04 FF 5A A5 2D
				39 00 00 40 00 00 03 8A 02 00
				39 00 00 00 00 00 04 FF 5A A5 00
			];
			qcom,mdss-dsi-adfr-min-fps-3-command = [
				/*15Hz*/
				39 00 00 40 00 00 04 FF 5A A5 2D
				39 00 00 40 00 00 03 8A 05 00
				39 00 00 00 00 00 04 FF 5A A5 00
			];
			qcom,mdss-dsi-adfr-min-fps-4-command = [
				/*10Hz*/
				39 00 00 40 00 00 04 FF 5A A5 2D
				39 00 00 40 00 00 03 8A 08 00
				39 00 00 00 00 00 04 FF 5A A5 00
			];
			qcom,mdss-dsi-adfr-min-fps-5-command = [
				/*5Hz*/
				39 00 00 40 00 00 04 FF 5A A5 2D
				39 00 00 40 00 00 03 8A 11 00
				39 00 00 00 00 00 04 FF 5A A5 00
			];
			qcom,mdss-dsi-adfr-min-fps-6-command = [
				/*1Hz*/
				39 00 00 40 00 00 04 FF 5A A5 2D
				39 00 00 40 00 00 03 8A 59 00
				39 00 00 00 00 00 04 FF 5A A5 00
			];
			qcom,mdss-dsi-hpwm-adfr-min-fps-0-command = [
				/*90Hz*/
				39 00 00 40 00 00 04 FF 5A A5 2D
				39 00 00 40 00 00 03 8F 00 00
				39 00 00 00 00 00 04 FF 5A A5 00
			];
			qcom,mdss-dsi-hpwm-adfr-min-fps-1-command = [
				//45Hz
				39 00 00 40 00 00 04 FF 5A A5 2D
				39 00 00 40 00 00 03 8F 01 00
				39 00 00 00 00 00 04 FF 5A A5 00
			];
			qcom,mdss-dsi-hpwm-adfr-min-fps-2-command = [
				//30Hz
				39 00 00 40 00 00 04 FF 5A A5 2D
				39 00 00 40 00 00 03 8F 02 00
				39 00 00 00 00 00 04 FF 5A A5 00
			];
			qcom,mdss-dsi-hpwm-adfr-min-fps-3-command = [
				//15Hz
				39 00 00 40 00 00 04 FF 5A A5 2D
				39 00 00 40 00 00 03 8F 05 00
				39 00 00 00 00 00 04 FF 5A A5 00
			];
			qcom,mdss-dsi-hpwm-adfr-min-fps-4-command = [
				//10Hz
				39 00 00 40 00 00 04 FF 5A A5 2D
				39 00 00 40 00 00 03 8F 08 00
				39 00 00 00 00 00 04 FF 5A A5 00
			];
			qcom,mdss-dsi-hpwm-adfr-min-fps-5-command = [
				//5Hz
				39 00 00 40 00 00 04 FF 5A A5 2D
				39 00 00 40 00 00 03 8F 11 00
				39 00 00 00 00 00 04 FF 5A A5 00
			];
			qcom,mdss-dsi-hpwm-adfr-min-fps-6-command = [
				//1Hz
				39 00 00 40 00 00 04 FF 5A A5 2D
				39 00 00 40 00 00 03 8F 59 00
				39 00 00 00 00 00 04 FF 5A A5 00
			];
			qcom,mdss-dsi-bigdc-adfr-min-fps-0-command = [
				/*90Hz*/
				39 00 00 40 00 00 04 FF 5A A5 2D
				39 00 00 40 00 00 03 8F 00 00
				39 00 00 00 00 00 04 FF 5A A5 00
			];
			qcom,mdss-dsi-bigdc-adfr-min-fps-1-command = [
				//45Hz
				39 00 00 40 00 00 04 FF 5A A5 2D
				39 00 00 40 00 00 03 8F 01 00
				39 00 00 00 00 00 04 FF 5A A5 00
			];
			qcom,mdss-dsi-bigdc-adfr-min-fps-2-command = [
				//30Hz
				39 00 00 40 00 00 04 FF 5A A5 2D
				39 00 00 40 00 00 03 8F 02 00
				39 00 00 00 00 00 04 FF 5A A5 00
			];
			qcom,mdss-dsi-bigdc-adfr-min-fps-3-command = [
				//15Hz
				39 00 00 40 00 00 04 FF 5A A5 2D
				39 00 00 40 00 00 03 8F 05 00
				39 00 00 00 00 00 04 FF 5A A5 00
			];
			qcom,mdss-dsi-bigdc-adfr-min-fps-4-command = [
				//10Hz
				39 00 00 40 00 00 04 FF 5A A5 2D
				39 00 00 40 00 00 03 8F 08 00
				39 00 00 00 00 00 04 FF 5A A5 00
			];
			qcom,mdss-dsi-bigdc-adfr-min-fps-5-command = [
				//5Hz
				39 00 00 40 00 00 04 FF 5A A5 2D
				39 00 00 40 00 00 03 8F 11 00
				39 00 00 00 00 00 04 FF 5A A5 00
			];
			qcom,mdss-dsi-bigdc-adfr-min-fps-6-command = [
				//1Hz
				39 00 00 40 00 00 04 FF 5A A5 2D
				39 00 00 40 00 00 03 8F 59 00
				39 00 00 00 00 00 04 FF 5A A5 00
			];

			qcom,mdss-dsi-adfr-pre-switch-command-state = "dsi_hs_mode";
			qcom,mdss-dsi-adfr-min-fps-0-command-state = "dsi_hs_mode";
			qcom,mdss-dsi-adfr-min-fps-1-command-state = "dsi_hs_mode";
			qcom,mdss-dsi-adfr-min-fps-2-command-state = "dsi_hs_mode";
			qcom,mdss-dsi-adfr-min-fps-3-command-state = "dsi_hs_mode";
			qcom,mdss-dsi-adfr-min-fps-4-command-state = "dsi_hs_mode";
			qcom,mdss-dsi-adfr-min-fps-5-command-state = "dsi_hs_mode";
			qcom,mdss-dsi-adfr-min-fps-6-command-state = "dsi_hs_mode";
			qcom,mdss-dsi-hpwm-adfr-min-fps-0-command-state = "dsi_hs_mode";
			qcom,mdss-dsi-hpwm-adfr-min-fps-1-command-state = "dsi_hs_mode";
			qcom,mdss-dsi-hpwm-adfr-min-fps-2-command-state = "dsi_hs_mode";
			qcom,mdss-dsi-hpwm-adfr-min-fps-3-command-state = "dsi_hs_mode";
			qcom,mdss-dsi-hpwm-adfr-min-fps-4-command-state = "dsi_hs_mode";
			qcom,mdss-dsi-hpwm-adfr-min-fps-5-command-state = "dsi_hs_mode";
			qcom,mdss-dsi-hpwm-adfr-min-fps-6-command-state = "dsi_hs_mode";
			qcom,mdss-dsi-bigdc-adfr-min-fps-0-command-state = "dsi_hs_mode";
			qcom,mdss-dsi-bigdc-adfr-min-fps-1-command-state = "dsi_hs_mode";
			qcom,mdss-dsi-bigdc-adfr-min-fps-2-command-state = "dsi_hs_mode";
			qcom,mdss-dsi-bigdc-adfr-min-fps-3-command-state = "dsi_hs_mode";
			qcom,mdss-dsi-bigdc-adfr-min-fps-4-command-state = "dsi_hs_mode";
			qcom,mdss-dsi-bigdc-adfr-min-fps-5-command-state = "dsi_hs_mode";
			qcom,mdss-dsi-bigdc-adfr-min-fps-6-command-state = "dsi_hs_mode";
		};
		timing@wqhd_sdc_60 {
			/* SDC ADFR */
			qcom,mdss-dsi-h-sync-skew = <1>;
			oplus,adfr-min-fps-mapping-table = <60 30 20 10 5 1>;
			qcom,mdss-dsi-adfr-pre-switch-command = [
				39 00 00 40 00 00 04 FF 5A A5 2D
				39 00 00 40 00 00 03 83 01 00
				39 00 00 40 00 00 03 8E 01 00
				39 00 00 00 00 00 04 FF 5A A5 00
			];
			qcom,mdss-dsi-adfr-min-fps-0-command = [
				/*60Hz*/
				39 00 00 40 00 00 04 FF 5A A5 2D
				39 00 00 40 00 00 03 83 01 00
				39 00 00 00 00 00 04 FF 5A A5 00
			];
			qcom,mdss-dsi-adfr-min-fps-1-command = [
				/*30Hz*/
				39 00 00 40 00 00 04 FF 5A A5 2D
				39 00 00 40 00 00 03 83 03 00
				39 00 00 00 00 00 04 FF 5A A5 00
			];
			qcom,mdss-dsi-adfr-min-fps-2-command = [
				/*20Hz*/
				39 00 00 40 00 00 04 FF 5A A5 2D
				39 00 00 40 00 00 03 83 05 00
				39 00 00 00 00 00 04 FF 5A A5 00
			];
			qcom,mdss-dsi-adfr-min-fps-3-command = [
				/*10Hz*/
				39 00 00 40 00 00 04 FF 5A A5 2D
				39 00 00 40 00 00 03 83 0B 00
				39 00 00 00 00 00 04 FF 5A A5 00
			];
			qcom,mdss-dsi-adfr-min-fps-4-command = [
				/*5Hz*/
				39 00 00 40 00 00 04 FF 5A A5 2D
				39 00 00 40 00 00 03 83 17 00
				39 00 00 00 00 00 04 FF 5A A5 00
			];
			qcom,mdss-dsi-adfr-min-fps-5-command = [
				/*1Hz*/
				39 00 00 40 00 00 04 FF 5A A5 2D
				39 00 00 40 00 00 03 83 77 00
				39 00 00 00 00 00 04 FF 5A A5 00
			];
			qcom,mdss-dsi-hpwm-adfr-min-fps-0-command = [
				/*60Hz*/
				39 00 00 40 00 00 04 FF 5A A5 2D
				39 00 00 40 00 00 03 83 01 00
				39 00 00 00 00 00 04 FF 5A A5 00
			];
			qcom,mdss-dsi-hpwm-adfr-min-fps-1-command = [
				/*30Hz*/
				39 00 00 40 00 00 04 FF 5A A5 2D
				39 00 00 40 00 00 03 83 03 00
				39 00 00 00 00 00 04 FF 5A A5 00
			];
			qcom,mdss-dsi-hpwm-adfr-min-fps-2-command = [
				/*20Hz*/
				39 00 00 40 00 00 04 FF 5A A5 2D
				39 00 00 40 00 00 03 83 05 00
				39 00 00 00 00 00 04 FF 5A A5 00
			];
			qcom,mdss-dsi-hpwm-adfr-min-fps-3-command = [
				/*10Hz*/
				39 00 00 40 00 00 04 FF 5A A5 2D
				39 00 00 40 00 00 03 83 0B 00
				39 00 00 00 00 00 04 FF 5A A5 00
			];
			qcom,mdss-dsi-hpwm-adfr-min-fps-4-command = [
				/*5Hz*/
				39 00 00 40 00 00 04 FF 5A A5 2D
				39 00 00 40 00 00 03 83 17 00
				39 00 00 00 00 00 04 FF 5A A5 00
			];
			qcom,mdss-dsi-hpwm-adfr-min-fps-5-command = [
				/*1Hz*/
				39 00 00 40 00 00 04 FF 5A A5 2D
				39 00 00 40 00 00 03 83 77 00
				39 00 00 00 00 00 04 FF 5A A5 00
			];
			qcom,mdss-dsi-bigdc-adfr-min-fps-0-command = [
				/*60Hz*/
				39 00 00 40 00 00 04 FF 5A A5 2D
				39 00 00 40 00 00 03 8E 01 00
				39 00 00 00 00 00 04 FF 5A A5 00
			];
			qcom,mdss-dsi-bigdc-adfr-min-fps-1-command = [
				/*30Hz*/
				39 00 00 40 00 00 04 FF 5A A5 2D
				39 00 00 40 00 00 03 8E 03 00
				39 00 00 00 00 00 04 FF 5A A5 00
			];
			qcom,mdss-dsi-bigdc-adfr-min-fps-2-command = [
				/*20Hz*/
				39 00 00 40 00 00 04 FF 5A A5 2D
				39 00 00 40 00 00 03 8E 05 00
				39 00 00 00 00 00 04 FF 5A A5 00
			];
			qcom,mdss-dsi-bigdc-adfr-min-fps-3-command = [
				/*10Hz*/
				39 00 00 40 00 00 04 FF 5A A5 2D
				39 00 00 40 00 00 03 8E 0B 00
				39 00 00 00 00 00 04 FF 5A A5 00
			];
			qcom,mdss-dsi-bigdc-adfr-min-fps-4-command = [
				/*5Hz*/
				39 00 00 40 00 00 04 FF 5A A5 2D
				39 00 00 40 00 00 03 8E 17 00
				39 00 00 00 00 00 04 FF 5A A5 00
			];
			qcom,mdss-dsi-bigdc-adfr-min-fps-5-command = [
				/*1Hz*/
				39 00 00 40 00 00 04 FF 5A A5 2D
				39 00 00 40 00 00 03 8E 77 00
				39 00 00 00 00 00 04 FF 5A A5 00
			];

			qcom,mdss-dsi-adfr-pre-switch-command-state = "dsi_hs_mode";
			qcom,mdss-dsi-adfr-min-fps-0-command-state = "dsi_hs_mode";
			qcom,mdss-dsi-adfr-min-fps-1-command-state = "dsi_hs_mode";
			qcom,mdss-dsi-adfr-min-fps-2-command-state = "dsi_hs_mode";
			qcom,mdss-dsi-adfr-min-fps-3-command-state = "dsi_hs_mode";
			qcom,mdss-dsi-adfr-min-fps-4-command-state = "dsi_hs_mode";
			qcom,mdss-dsi-adfr-min-fps-5-command-state = "dsi_hs_mode";
			qcom,mdss-dsi-hpwm-adfr-min-fps-0-command-state = "dsi_hs_mode";
			qcom,mdss-dsi-hpwm-adfr-min-fps-1-command-state = "dsi_hs_mode";
			qcom,mdss-dsi-hpwm-adfr-min-fps-2-command-state = "dsi_hs_mode";
			qcom,mdss-dsi-hpwm-adfr-min-fps-3-command-state = "dsi_hs_mode";
			qcom,mdss-dsi-hpwm-adfr-min-fps-4-command-state = "dsi_hs_mode";
			qcom,mdss-dsi-hpwm-adfr-min-fps-5-command-state = "dsi_hs_mode";
			qcom,mdss-dsi-bigdc-adfr-min-fps-0-command-state = "dsi_hs_mode";
			qcom,mdss-dsi-bigdc-adfr-min-fps-1-command-state = "dsi_hs_mode";
			qcom,mdss-dsi-bigdc-adfr-min-fps-2-command-state = "dsi_hs_mode";
			qcom,mdss-dsi-bigdc-adfr-min-fps-3-command-state = "dsi_hs_mode";
			qcom,mdss-dsi-bigdc-adfr-min-fps-4-command-state = "dsi_hs_mode";
			qcom,mdss-dsi-bigdc-adfr-min-fps-5-command-state = "dsi_hs_mode";
		};
		timing@wqhd_oplus_120 {
			/* OPLUS ADFR */
			qcom,mdss-dsi-h-sync-skew = <2>;
			oplus,adfr-min-fps-mapping-table = <120 30>;

			qcom,mdss-dsi-adfr-pre-switch-command = [
				39 00 00 40 00 00 04 FF 5A A5 2D
				39 00 00 40 00 00 03 83 00 00
				39 00 00 40 00 00 03 8E 00 00
				39 00 00 00 00 00 04 FF 5A A5 00
			];
			qcom,mdss-dsi-adfr-min-fps-0-command = [
				/*120Hz*/
				39 00 00 40 00 00 04 FF 5A A5 2D
				39 00 00 40 00 00 03 83 00 00
				39 00 00 00 00 00 04 FF 5A A5 00
			];
			qcom,mdss-dsi-adfr-min-fps-1-command = [
				/*30Hz*/
				39 00 00 40 00 00 04 FF 5A A5 2D
				39 00 00 40 00 00 03 83 03 00
				39 00 00 00 00 00 04 FF 5A A5 00
			];
			qcom,mdss-dsi-hpwm-adfr-min-fps-0-command = [
				/*120Hz*/
				39 00 00 40 00 00 04 FF 5A A5 2D
				39 00 00 40 00 00 03 83 00 00
				39 00 00 00 00 00 04 FF 5A A5 00
			];
			qcom,mdss-dsi-hpwm-adfr-min-fps-1-command = [
				/*30Hz*/
				39 00 00 40 00 00 04 FF 5A A5 2D
				39 00 00 40 00 00 03 83 03 00
				39 00 00 00 00 00 04 FF 5A A5 00
			];
			qcom,mdss-dsi-bigdc-adfr-min-fps-0-command = [
				/*120Hz*/
				39 00 00 40 00 00 04 FF 5A A5 2D
				39 00 00 40 00 00 03 8E 00 00
				39 00 00 00 00 00 04 FF 5A A5 00
			];
			qcom,mdss-dsi-bigdc-adfr-min-fps-1-command = [
				/*30Hz*/
				39 00 00 40 00 00 04 FF 5A A5 2D
				39 00 00 40 00 00 03 8E 03 00
				39 00 00 00 00 00 04 FF 5A A5 00
			];
			qcom,mdss-dsi-qsync-off-commands = [
				/*120Hz*/
				39 00 00 40 00 00 04 FF 5A A5 2D
				39 00 00 40 00 00 03 83 03 00
				39 00 00 40 00 00 03 8E 00 00
				39 00 00 00 00 00 04 FF 5A A5 00
			];

			qcom,mdss-dsi-adfr-pre-switch-command-state = "dsi_hs_mode";
			qcom,mdss-dsi-adfr-min-fps-0-command-state = "dsi_hs_mode";
			qcom,mdss-dsi-adfr-min-fps-1-command-state = "dsi_hs_mode";
			qcom,mdss-dsi-hpwm-adfr-min-fps-0-command-state = "dsi_hs_mode";
			qcom,mdss-dsi-hpwm-adfr-min-fps-1-command-state = "dsi_hs_mode";
			qcom,mdss-dsi-bigdc-adfr-min-fps-0-command-state = "dsi_hs_mode";
			qcom,mdss-dsi-bigdc-adfr-min-fps-1-command-state = "dsi_hs_mode";
			qcom,mdss-dsi-qsync-off-commands-state = "dsi_hs_mode";
		};
	};
};

&dsi_panel_AA569_P_3_A0019_dsc_cmd {
	/* HARDWARE CONFIG */
	qcom,panel-supply-entries = <&oplus_dsi_panel_custom_pwr_supply>;
	qcom,mdss-dsi-panel-controller = <&mdss_dsi0>;
	qcom,platform-te-gpio = <&tlmm 86 0>;
	qcom,platform-reset-gpio = <&tlmm 98 0>;
	oplus,panel-gpio1  = <&pm8550ve_f_gpios 7 0>;

	oplus,panel-reset-position = <0x02>;
	oplus,panel-power-on-sequence = "1", "vddio", "3", "gpio1", "3", "vci", "10";
	oplus,panel-power-off-sequence = "1", "vci", "3", "gpio1", "3", "vddio", "1";

	qcom,panel_voltage_vddi_name = "vddio";
	qcom,panel_voltage_vddi = <1 1750000 1850000 1950000>;
	qcom,panel_voltage_vddr_name = "vci";
	qcom,panel_voltage_vddr = <1 3000000 3200000 3300000>;

	/* BRIGHTNESS CONFIG */
	qcom,mdss-dsi-bl-pmic-control-type = "bl_ctrl_dcs";
	qcom,bl-dsc-cmd-state = "dsi_hs_mode";
	qcom,mdss-dsi-bl-inverted-dbv;
	qcom,mdss-dsi-bl-min-level = <1>;
	qcom,mdss-dsi-bl-max-level = <4094>;
	qcom,mdss-brightness-max-level = <4094>;
	oplus,dsi-bl-normal-max-level = <3515>;
	oplus,dsi-brightness-normal-max-level = <3515>;
	oplus,dsi-brightness-default-level = <1433>;
	oplus,dsi-dc-backlight-threshold = <1102>;
	oplus,dsi-global-hbm-case-id = <1>;
	//oplus,dsi-global-hbm-case23-threshold = <2048>;

	/* ESD CONFIG */
	qcom,esd-check-enabled;
	qcom,mdss-dsi-panel-status-check-mode = "reg_read";
	qcom,mdss-dsi-panel-status-command = [
		06 00 00 00 00 00 01 0A
	];
	qcom,mdss-dsi-panel-status-command-state = "dsi_lp_mode";
	qcom,mdss-dsi-panel-status-value = <
		0x9C
	>;
	qcom,mdss-dsi-panel-status-read-length = <1>;
	oplus,mdss-dsi-panel-status-match-modes = <0x00000000>;

	/* MIPI ERR check config */
	/*  BIT(0): enable/disable check
	 ** BIT(1): enable/disable page switch
	 */
	oplus,mipi-err-check-config = <0x03>; // 0b0000'0011
	oplus,mipi-err-check-reg = [
		05
	];
	oplus,mipi-err-check-value = [
		00
	];
	oplus,mipi-err-check-count = [
		01
	];
	/* 32-bit binary flag
	 ** Bit value identified how to match the return value of each register.
	 ** The value 0(default) means equal, and the value 1 means not equal.
	 */
	oplus,mipi-err-check-match-modes = <0x00000000>;

	/* FACTORY CONFIG */
	oplus,mdss-dsi-vendor-name = "A0019";
	oplus,mdss-dsi-manufacture = "P_3";
	oplus,color_vivid_status;
	oplus,color_srgb_status;
	//oplus,color_softiris_status;
	oplus,color_oplus_calibrate_status;
	oplus,color_dual_brightness_status;
	oplus,color_2nit_status;
	oplus,color_loading_status;
	//oplus,color_nature_profession_status;
	oplus,mdss-dsi-panel-type = <0>;

	/* OPLUS FEATURES CONFIG */
	oplus,apl-read-support;
	oplus,dp-enabled;
	//oplus,dsi-cabc-enabled;
	//oplus,dsi-dre-enabled;
	oplus,dsi-serial-number-enabled;
	//oplus,dsi-serial-number-lock;
	oplus,dsi-serial-number-switch-page;
	oplus,dsi-serial-number-reg= <0x82>;
	oplus,dsi-serial-number-index= <0>;
	oplus,dsi-serial-number-read-count= <7>;


	/* btb-sn config */
	oplus,dsi-btb-sn-enabled;
	oplus,dsi-btb-sn-switch-page;
	oplus,dsi-btb-sn-reg= <0x80>;
	oplus,dsi-btb-sn-index= <0>;
	oplus,dsi-btb-sn-read-count= <32>;

	/* adfr config */
	oplus,adfr-config = <0x1041>;  // 0b0001'0000'0100'0001
	oplus,adfr-test-te-gpio = <&tlmm 85 0>;
	/* just for qsync enable */
	qcom,qsync-enable;
	qcom,mdss-dsi-qsync-min-refresh-rate = <30>;

	/* pwm config */
	/*	oplus,pwm-switch-config:
		Bit0: pwm feature enable
		Bit1: pwm mode switch enable, need to config switch cmds
		Bit2: force enabled pwm mode switch cmd, will send mode cmd even dbv threshold cmd feature is configed
		Bit3: pwm dbv threshold pulse switch enable, need to config threshold switch cmds
		Bit4: wait te before sending pwm dbv threshold pulse switch cmd
		Bit5: replace specific cmd to other cmd while in pwm 1pulse mode
		Bit6: sending extend cmd while panel power on accroding to current pwm mode
		Bit7: sending extend cmd while timing switch accroding to current pwm pulse level
		Bit8: sending extend cmd after sending dbv threshold cmd in another thread
	*/
	oplus,pwm-switch-config = <0x67>;
	/*	oplus,pwm-switch-mode0-states-info/oplus,pwm-switch-mode1-states-info:
		Specific dbv threshold and pulse info of 2 pwm mode, for pulse, 0 symbols 1pulse,
		1symbols 3pulse and 2 symbols 18pulse. The format should be 1 dbv threshold info with
		2 pwm pulse levels left and right(for example, <2 1087 1> means 18pulse while dbv <= 1087
		and 3pulse while dbv > 1087), or only one pulse level, no threshold.
	*/
	oplus,pwm-switch-mode0-states-info = <2 1100 1>;
	oplus,pwm-switch-mode1-states-info = <2 1100 0>;
	oplus,pwm-switch-mode2-states-info = <0>;
	/*	oplus,pwm-cmd-switch-map:
		Specific cmd replace relationship while in switch on(1pulse) mode. It is a string array that
		compose with cmd names, every 2 names combine 1 map. For example, map "'a', 'b'" means replace
		a to b while sending a in switch on mode.
	*/
	oplus,pwm-cmd-switch-map = "qcom,mdss-dsi-lp1-command", "qcom,mdss-dsi-aod-on-1pulse-command",
			"qcom,mdss-dsi-nolp-command", "qcom,mdss-dsi-aod-off-1pulse-command",
			"qcom,mdss-dsi-timing-switch-command", "qcom,mdss-dsi-timming-pwm-switch-onepulse-command";

	oplus,pwm-compatible-mode;
	oplus,cmdq-sync-support;
	/* ofp config */
	oplus,ofp-fp-type = <0xc0>;
	oplus,ofp-longrui-aod-config = <0x02>;
	oplus,ofp-need-to-bypass-gamut;
	oplus,ofp-need-to-wait-data-before-aod-on;

	oplus,dsi-panel-id-switch-page;

	oplus,gamma-compensation-support;

	/* SPR CONFIG */
	qcom,spr-pack-type = "pentile";
};
